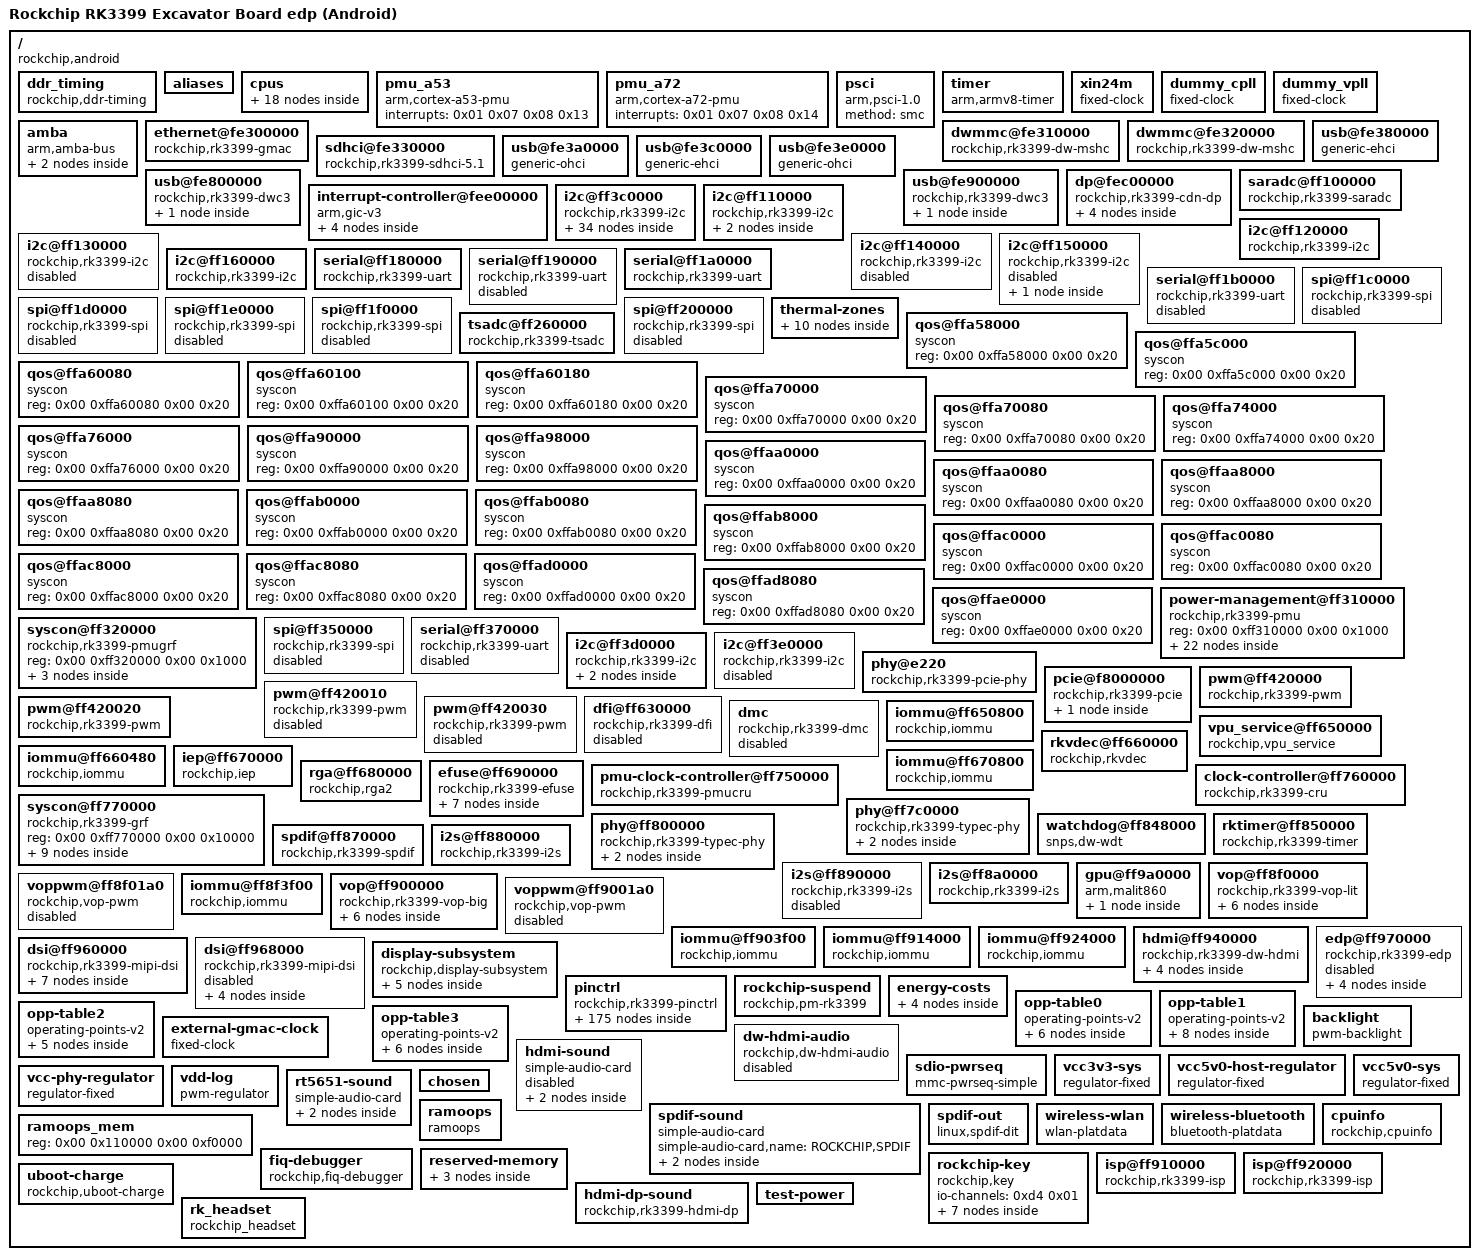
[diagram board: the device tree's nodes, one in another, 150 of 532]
/dts-v1/;

/ {
	compatible = "rockchip,android\0rockchip,rk3399-excavator-edp\0rockchip,rk3399";
	interrupt-parent = < 0x01 >;
	#address-cells = < 0x02 >;
	#size-cells = < 0x02 >;
	model = "Rockchip RK3399 Excavator Board edp (Android)";

	ddr_timing {
		compatible = "rockchip,ddr-timing";
		ddr3_speed_bin = < 0x15 >;
		pd_idle = < 0x00 >;
		sr_idle = < 0x00 >;
		sr_mc_gate_idle = < 0x00 >;
		srpd_lite_idle = < 0x00 >;
		standby_idle = < 0x00 >;
		auto_lp_dis_freq = < 0x29a >;
		ddr3_dll_dis_freq = < 0x12c >;
		phy_dll_dis_freq = < 0x104 >;
		ddr3_odt_dis_freq = < 0x29a >;
		ddr3_drv = < 0x28 >;
		ddr3_odt = < 0x78 >;
		phy_ddr3_ca_drv = < 0x28 >;
		phy_ddr3_dq_drv = < 0x28 >;
		phy_ddr3_odt = < 0xf0 >;
		lpddr3_odt_dis_freq = < 0x29a >;
		lpddr3_drv = < 0x22 >;
		lpddr3_odt = < 0xf0 >;
		phy_lpddr3_ca_drv = < 0x22 >;
		phy_lpddr3_dq_drv = < 0x22 >;
		phy_lpddr3_odt = < 0xf0 >;
		lpddr4_odt_dis_freq = < 0x3a5 >;
		lpddr4_drv = < 0x3c >;
		lpddr4_dq_odt = < 0x28 >;
		lpddr4_ca_odt = < 0x28 >;
		phy_lpddr4_ca_drv = < 0x28 >;
		phy_lpddr4_ck_cs_drv = < 0x50 >;
		phy_lpddr4_dq_drv = < 0x50 >;
		phy_lpddr4_odt = < 0x3c >;
		linux,phandle = < 0x8f >;
		phandle = < 0x8f >;
	};

	aliases {
		i2c0 = "/i2c@ff3c0000";
		i2c1 = "/i2c@ff110000";
		i2c2 = "/i2c@ff120000";
		i2c3 = "/i2c@ff130000";
		i2c4 = "/i2c@ff3d0000";
		i2c5 = "/i2c@ff140000";
		i2c6 = "/i2c@ff150000";
		i2c7 = "/i2c@ff160000";
		i2c8 = "/i2c@ff3e0000";
		serial0 = "/serial@ff180000";
		serial1 = "/serial@ff190000";
		serial2 = "/serial@ff1a0000";
		serial3 = "/serial@ff1b0000";
		serial4 = "/serial@ff370000";
		dsi0 = "/dsi@ff960000";
		dsi1 = "/dsi@ff968000";
	};

	cpus {
		#address-cells = < 0x02 >;
		#size-cells = < 0x00 >;

		cpu-map {

			cluster0 {

				core0 {
					cpu = < 0x02 >;
				};

				core1 {
					cpu = < 0x03 >;
				};

				core2 {
					cpu = < 0x04 >;
				};

				core3 {
					cpu = < 0x05 >;
				};
			};

			cluster1 {

				core0 {
					cpu = < 0x06 >;
				};

				core1 {
					cpu = < 0x07 >;
				};
			};
		};

		cpu@0 {
			device_type = "cpu";
			compatible = "arm,cortex-a53\0arm,armv8";
			reg = < 0x00 0x00 >;
			enable-method = "psci";
			#cooling-cells = < 0x02 >;
			dynamic-power-coefficient = < 0x64 >;
			clocks = < 0x08 0x08 >;
			cpu-idle-states = < 0x09 0x0a >;
			operating-points-v2 = < 0x0b >;
			sched-energy-costs = < 0x0c 0x0d >;
			cpu-supply = < 0x0e >;
			linux,phandle = < 0x02 >;
			phandle = < 0x02 >;
		};

		cpu@1 {
			device_type = "cpu";
			compatible = "arm,cortex-a53\0arm,armv8";
			reg = < 0x00 0x01 >;
			enable-method = "psci";
			clocks = < 0x08 0x08 >;
			cpu-idle-states = < 0x09 0x0a >;
			operating-points-v2 = < 0x0b >;
			sched-energy-costs = < 0x0c 0x0d >;
			cpu-supply = < 0x0e >;
			linux,phandle = < 0x03 >;
			phandle = < 0x03 >;
		};

		cpu@2 {
			device_type = "cpu";
			compatible = "arm,cortex-a53\0arm,armv8";
			reg = < 0x00 0x02 >;
			enable-method = "psci";
			clocks = < 0x08 0x08 >;
			cpu-idle-states = < 0x09 0x0a >;
			operating-points-v2 = < 0x0b >;
			sched-energy-costs = < 0x0c 0x0d >;
			cpu-supply = < 0x0e >;
			linux,phandle = < 0x04 >;
			phandle = < 0x04 >;
		};

		cpu@3 {
			device_type = "cpu";
			compatible = "arm,cortex-a53\0arm,armv8";
			reg = < 0x00 0x03 >;
			enable-method = "psci";
			clocks = < 0x08 0x08 >;
			cpu-idle-states = < 0x09 0x0a >;
			operating-points-v2 = < 0x0b >;
			sched-energy-costs = < 0x0c 0x0d >;
			cpu-supply = < 0x0e >;
			linux,phandle = < 0x05 >;
			phandle = < 0x05 >;
		};

		cpu@100 {
			device_type = "cpu";
			compatible = "arm,cortex-a72\0arm,armv8";
			reg = < 0x00 0x100 >;
			enable-method = "psci";
			#cooling-cells = < 0x02 >;
			dynamic-power-coefficient = < 0x1b4 >;
			clocks = < 0x08 0x09 >;
			cpu-idle-states = < 0x09 0x0a >;
			operating-points-v2 = < 0x0f >;
			sched-energy-costs = < 0x10 0x11 >;
			cpu-supply = < 0x12 >;
			linux,phandle = < 0x06 >;
			phandle = < 0x06 >;
		};

		cpu@101 {
			device_type = "cpu";
			compatible = "arm,cortex-a72\0arm,armv8";
			reg = < 0x00 0x101 >;
			enable-method = "psci";
			clocks = < 0x08 0x09 >;
			cpu-idle-states = < 0x09 0x0a >;
			operating-points-v2 = < 0x0f >;
			sched-energy-costs = < 0x10 0x11 >;
			cpu-supply = < 0x12 >;
			linux,phandle = < 0x07 >;
			phandle = < 0x07 >;
		};

		idle-states {
			entry-method = "psci";

			cpu-sleep {
				compatible = "arm,idle-state";
				local-timer-stop;
				arm,psci-suspend-param = < 0x10000 >;
				entry-latency-us = < 0x78 >;
				exit-latency-us = < 0xfa >;
				min-residency-us = < 0x384 >;
				linux,phandle = < 0x09 >;
				phandle = < 0x09 >;
			};

			cluster-sleep {
				compatible = "arm,idle-state";
				local-timer-stop;
				arm,psci-suspend-param = < 0x1010000 >;
				entry-latency-us = < 0x190 >;
				exit-latency-us = < 0x1f4 >;
				min-residency-us = < 0x7d0 >;
				linux,phandle = < 0x0a >;
				phandle = < 0x0a >;
			};
		};
	};

	pmu_a53 {
		compatible = "arm,cortex-a53-pmu";
		interrupts = < 0x01 0x07 0x08 0x13 >;
	};

	pmu_a72 {
		compatible = "arm,cortex-a72-pmu";
		interrupts = < 0x01 0x07 0x08 0x14 >;
	};

	psci {
		compatible = "arm,psci-1.0";
		method = "smc";
	};

	timer {
		compatible = "arm,armv8-timer";
		interrupts = < 0x01 0x0d 0x08 0x00 0x01 0x0e 0x08 0x00 0x01 0x0b 0x08 0x00 0x01 0x0a 0x08 0x00 >;
	};

	xin24m {
		compatible = "fixed-clock";
		clock-frequency = < 0x16e3600 >;
		clock-output-names = "xin24m";
		#clock-cells = < 0x00 >;
	};

	dummy_cpll {
		compatible = "fixed-clock";
		clock-frequency = < 0x00 >;
		clock-output-names = "dummy_cpll";
		#clock-cells = < 0x00 >;
	};

	dummy_vpll {
		compatible = "fixed-clock";
		clock-frequency = < 0x00 >;
		clock-output-names = "dummy_vpll";
		#clock-cells = < 0x00 >;
	};

	amba {
		compatible = "arm,amba-bus";
		#address-cells = < 0x02 >;
		#size-cells = < 0x02 >;
		ranges;

		dma-controller@ff6d0000 {
			compatible = "arm,pl330\0arm,primecell";
			reg = < 0x00 0xff6d0000 0x00 0x4000 >;
			interrupts = < 0x00 0x05 0x04 0x00 0x00 0x06 0x04 0x00 >;
			#dma-cells = < 0x01 >;
			clocks = < 0x08 0xd3 >;
			clock-names = "apb_pclk";
			peripherals-req-type-burst;
			linux,phandle = < 0x98 >;
			phandle = < 0x98 >;
		};

		dma-controller@ff6e0000 {
			compatible = "arm,pl330\0arm,primecell";
			reg = < 0x00 0xff6e0000 0x00 0x4000 >;
			interrupts = < 0x00 0x07 0x04 0x00 0x00 0x08 0x04 0x00 >;
			#dma-cells = < 0x01 >;
			clocks = < 0x08 0xd4 >;
			clock-names = "apb_pclk";
			peripherals-req-type-burst;
		};
	};

	ethernet@fe300000 {
		compatible = "rockchip,rk3399-gmac";
		reg = < 0x00 0xfe300000 0x00 0x10000 >;
		rockchip,grf = < 0x15 >;
		interrupts = < 0x00 0x0c 0x04 0x00 >;
		interrupt-names = "macirq";
		clocks = < 0x08 0x69 0x08 0x67 0x08 0x68 0x08 0x66 0x08 0x6a 0x08 0xd5 0x08 0x166 >;
		clock-names = "stmmaceth\0mac_clk_rx\0mac_clk_tx\0clk_mac_ref\0clk_mac_refout\0aclk_mac\0pclk_mac";
		resets = < 0x08 0x89 >;
		reset-names = "stmmaceth";
		power-domains = < 0x16 0x16 >;
		status = "okay";
		phy-supply = < 0x17 >;
		phy-mode = "rgmii";
		clock_in_out = "input";
		snps,reset-gpio = < 0x18 0x0f 0x01 >;
		snps,reset-active-low;
		snps,reset-delays-us = < 0x00 0x2710 0xc350 >;
		assigned-clocks = < 0x08 0xa6 >;
		assigned-clock-parents = < 0x19 >;
		pinctrl-names = "default";
		pinctrl-0 = < 0x1a >;
		tx_delay = < 0x28 >;
		rx_delay = < 0x11 >;
	};

	dwmmc@fe310000 {
		compatible = "rockchip,rk3399-dw-mshc\0rockchip,rk3288-dw-mshc";
		reg = < 0x00 0xfe310000 0x00 0x4000 >;
		interrupts = < 0x00 0x40 0x04 0x00 >;
		clock-freq-min-max = < 0x30d40 0x2faf080 >;
		clocks = < 0x08 0x1ee 0x08 0x4d 0x08 0x9c 0x08 0x9d >;
		clock-names = "biu\0ciu\0ciu-drive\0ciu-sample";
		fifo-depth = < 0x100 >;
		power-domains = < 0x16 0x1c >;
		status = "okay";
		clock-frequency = < 0x2faf080 >;
		supports-sdio;
		bus-width = < 0x04 >;
		disable-wp;
		cap-sd-highspeed;
		cap-sdio-irq;
		keep-power-in-suspend;
		mmc-pwrseq = < 0x1b >;
		non-removable;
		num-slots = < 0x01 >;
		pinctrl-names = "default";
		pinctrl-0 = < 0x1c 0x1d 0x1e >;
		sd-uhs-sdr104;
	};

	dwmmc@fe320000 {
		compatible = "rockchip,rk3399-dw-mshc\0rockchip,rk3288-dw-mshc";
		reg = < 0x00 0xfe320000 0x00 0x4000 >;
		interrupts = < 0x00 0x41 0x04 0x00 >;
		clock-freq-min-max = < 0x186a0 0x8f0d180 >;
		clocks = < 0x08 0x1ce 0x08 0x4c 0x08 0x9a 0x08 0x9b >;
		clock-names = "biu\0ciu\0ciu-drive\0ciu-sample";
		fifo-depth = < 0x100 >;
		power-domains = < 0x16 0x1b >;
		status = "okay";
		clock-frequency = < 0x8f0d180 >;
		supports-sd;
		bus-width = < 0x04 >;
		cap-mmc-highspeed;
		cap-sd-highspeed;
		disable-wp;
		num-slots = < 0x01 >;
		vqmmc-supply = < 0x1f >;
		pinctrl-names = "default";
		pinctrl-0 = < 0x20 0x21 0x22 0x23 >;
	};

	sdhci@fe330000 {
		compatible = "rockchip,rk3399-sdhci-5.1\0arasan,sdhci-5.1";
		reg = < 0x00 0xfe330000 0x00 0x10000 >;
		interrupts = < 0x00 0x0b 0x04 0x00 >;
		arasan,soc-ctl-syscon = < 0x15 >;
		assigned-clocks = < 0x08 0x4e >;
		assigned-clock-rates = < 0xbebc200 >;
		clocks = < 0x08 0x4e 0x08 0xf0 >;
		clock-names = "clk_xin\0clk_ahb";
		clock-output-names = "emmc_cardclock";
		#clock-cells = < 0x00 >;
		phys = < 0x24 >;
		phy-names = "phy_arasan";
		power-domains = < 0x16 0x17 >;
		status = "okay";
		bus-width = < 0x08 >;
		mmc-hs400-1_8v;
		supports-emmc;
		non-removable;
		keep-power-in-suspend;
		mmc-hs400-enhanced-strobe;
		assigned-clock-parents = < 0x08 0x05 >;
		linux,phandle = < 0x96 >;
		phandle = < 0x96 >;
	};

	usb@fe380000 {
		compatible = "generic-ehci";
		reg = < 0x00 0xfe380000 0x00 0x20000 >;
		interrupts = < 0x00 0x1a 0x04 0x00 >;
		clocks = < 0x08 0x1c8 0x08 0x1c9 0x08 0xa8 >;
		clock-names = "hclk_host0\0hclk_host0_arb\0usbphy0_480m";
		phys = < 0x25 >;
		phy-names = "usb";
		power-domains = < 0x16 0x0e >;
		status = "okay";
	};

	usb@fe3a0000 {
		compatible = "generic-ohci";
		reg = < 0x00 0xfe3a0000 0x00 0x20000 >;
		interrupts = < 0x00 0x1c 0x04 0x00 >;
		clocks = < 0x08 0x1c8 0x08 0x1c9 0x08 0xa8 >;
		clock-names = "hclk_host0\0hclk_host0_arb\0usbphy0_480m";
		phys = < 0x25 >;
		phy-names = "usb";
		power-domains = < 0x16 0x0e >;
		status = "okay";
	};

	usb@fe3c0000 {
		compatible = "generic-ehci";
		reg = < 0x00 0xfe3c0000 0x00 0x20000 >;
		interrupts = < 0x00 0x1e 0x04 0x00 >;
		clocks = < 0x08 0x1ca 0x08 0x1cb 0x08 0xa9 >;
		clock-names = "hclk_host1\0hclk_host1_arb\0usbphy1_480m";
		phys = < 0x26 >;
		phy-names = "usb";
		power-domains = < 0x16 0x0e >;
		status = "okay";
	};

	usb@fe3e0000 {
		compatible = "generic-ohci";
		reg = < 0x00 0xfe3e0000 0x00 0x20000 >;
		interrupts = < 0x00 0x20 0x04 0x00 >;
		clocks = < 0x08 0x1ca 0x08 0x1cb 0x08 0xa9 >;
		clock-names = "hclk_host1\0hclk_host1_arb\0usbphy1_480m";
		phys = < 0x26 >;
		phy-names = "usb";
		power-domains = < 0x16 0x0e >;
		status = "okay";
	};

	usb@fe800000 {
		compatible = "rockchip,rk3399-dwc3";
		clocks = < 0x08 0x81 0x08 0x83 0x08 0xf6 0x08 0xf9 >;
		clock-names = "ref_clk\0suspend_clk\0bus_clk\0grf_clk";
		power-domains = < 0x16 0x18 >;
		resets = < 0x08 0x125 >;
		reset-names = "usb3-otg";
		#address-cells = < 0x02 >;
		#size-cells = < 0x02 >;
		ranges;
		status = "okay";
		extcon = < 0x27 >;

		dwc3@fe800000 {
			compatible = "snps,dwc3";
			reg = < 0x00 0xfe800000 0x00 0x100000 >;
			interrupts = < 0x00 0x69 0x04 0x00 >;
			dr_mode = "otg";
			phys = < 0x28 0x29 >;
			phy-names = "usb2-phy\0usb3-phy";
			phy_type = "utmi_wide";
			snps,dis_enblslpm_quirk;
			snps,dis-u2-freeclk-exists-quirk;
			snps,dis_u2_susphy_quirk;
			snps,dis-del-phy-power-chg-quirk;
			snps,tx-ipgap-linecheck-dis-quirk;
			snps,xhci-slow-suspend-quirk;
			snps,usb3-warm-reset-on-resume-quirk;
			status = "okay";
		};
	};

	usb@fe900000 {
		compatible = "rockchip,rk3399-dwc3";
		clocks = < 0x08 0x82 0x08 0x84 0x08 0xf7 0x08 0xf9 >;
		clock-names = "ref_clk\0suspend_clk\0bus_clk\0grf_clk";
		power-domains = < 0x16 0x18 >;
		resets = < 0x08 0x126 >;
		reset-names = "usb3-otg";
		#address-cells = < 0x02 >;
		#size-cells = < 0x02 >;
		ranges;
		status = "okay";

		dwc3@fe900000 {
			compatible = "snps,dwc3";
			reg = < 0x00 0xfe900000 0x00 0x100000 >;
			interrupts = < 0x00 0x6e 0x04 0x00 >;
			dr_mode = "host";
			phys = < 0x2a 0x2b >;
			phy-names = "usb2-phy\0usb3-phy";
			phy_type = "utmi_wide";
			snps,dis_enblslpm_quirk;
			snps,dis-u2-freeclk-exists-quirk;
			snps,dis_u2_susphy_quirk;
			snps,dis-del-phy-power-chg-quirk;
			snps,tx-ipgap-linecheck-dis-quirk;
			snps,xhci-slow-suspend-quirk;
			snps,usb3-warm-reset-on-resume-quirk;
			status = "okay";
		};
	};

	dp@fec00000 {
		compatible = "rockchip,rk3399-cdn-dp";
		reg = < 0x00 0xfec00000 0x00 0x100000 >;
		interrupts = < 0x00 0x09 0x04 >;
		clocks = < 0x08 0x72 0x08 0x175 0x08 0xa1 0x08 0x16f >;
		clock-names = "core-clk\0pclk\0spdif\0grf";
		assigned-clocks = < 0x08 0x72 >;
		assigned-clock-rates = < 0x5f5e100 >;
		power-domains = < 0x16 0x15 >;
		phys = < 0x2c >;
		resets = < 0x08 0x103 0x08 0x148 0x08 0x14a 0x08 0xfd >;
		reset-names = "spdif\0dptx\0apb\0core";
		rockchip,grf = < 0x15 >;
		#address-cells = < 0x01 >;
		#size-cells = < 0x00 >;
		#sound-dai-cells = < 0x01 >;
		status = "okay";
		extcon = < 0x27 >;
		linux,phandle = < 0xdc >;
		phandle = < 0xdc >;

		ports {
			#address-cells = < 0x01 >;
			#size-cells = < 0x00 >;

			port {
				#address-cells = < 0x01 >;
				#size-cells = < 0x00 >;

				endpoint@0 {
					reg = < 0x00 >;
					remote-endpoint = < 0x2d >;
					status = "disabled";
					linux,phandle = < 0xa9 >;
					phandle = < 0xa9 >;
				};

				endpoint@1 {
					reg = < 0x01 >;
					remote-endpoint = < 0x2e >;
					linux,phandle = < 0xa2 >;
					phandle = < 0xa2 >;
				};
			};
		};
	};

	interrupt-controller@fee00000 {
		compatible = "arm,gic-v3";
		#interrupt-cells = < 0x04 >;
		#address-cells = < 0x02 >;
		#size-cells = < 0x02 >;
		ranges;
		interrupt-controller;
		reg = < 0x00 0xfee00000 0x00 0x10000 0x00 0xfef00000 0x00 0xc0000 0x00 0xfff00000 0x00 0x10000 0x00 0xfff10000 0x00 0x10000 0x00 0xfff20000 0x00 0x10000 >;
		interrupts = < 0x01 0x09 0x04 0x00 >;
		linux,phandle = < 0x01 >;
		phandle = < 0x01 >;

		interrupt-controller@fee20000 {
			compatible = "arm,gic-v3-its";
			msi-controller;
			reg = < 0x00 0xfee20000 0x00 0x20000 >;
			linux,phandle = < 0x84 >;
			phandle = < 0x84 >;
		};

		ppi-partitions {

			interrupt-partition-0 {
				affinity = < 0x02 0x03 0x04 0x05 >;
				linux,phandle = < 0x13 >;
				phandle = < 0x13 >;
			};

			interrupt-partition-1 {
				affinity = < 0x06 0x07 >;
				linux,phandle = < 0x14 >;
				phandle = < 0x14 >;
			};
		};
	};

	saradc@ff100000 {
		compatible = "rockchip,rk3399-saradc";
		reg = < 0x00 0xff100000 0x00 0x100 >;
		interrupts = < 0x00 0x3e 0x04 0x00 >;
		#io-channel-cells = < 0x01 >;
		clocks = < 0x08 0x50 0x08 0x165 >;
		clock-names = "saradc\0apb_pclk";
		resets = < 0x08 0xd4 >;
		reset-names = "saradc-apb";
		status = "okay";
		linux,phandle = < 0xd4 >;
		phandle = < 0xd4 >;
	};

	i2c@ff3c0000 {
		compatible = "rockchip,rk3399-i2c";
		reg = < 0x00 0xff3c0000 0x00 0x1000 >;
		clocks = < 0x2f 0x09 0x2f 0x1b >;
		clock-names = "i2c\0pclk";
		interrupts = < 0x00 0x39 0x04 0x00 >;
		pinctrl-names = "default";
		pinctrl-0 = < 0x30 >;
		#address-cells = < 0x01 >;
		#size-cells = < 0x00 >;
		status = "okay";
		i2c-scl-rising-time-ns = < 0xa8 >;
		i2c-scl-falling-time-ns = < 0x04 >;
		clock-frequency = < 0x61a80 >;

		syr827@40 {
			compatible = "silergy,syr827";
			reg = < 0x40 >;
			vin-supply = < 0x31 >;
			regulator-compatible = "fan53555-reg";
			pinctrl-names = "default";
			pinctrl-0 = < 0x32 >;
			vsel-gpios = < 0x33 0x11 0x00 >;
			regulator-name = "vdd_cpu_b";
			regulator-min-microvolt = < 0xadf34 >;
			regulator-max-microvolt = < 0x16e360 >;
			regulator-ramp-delay = < 0x3e8 >;
			fcs,suspend-voltage-selector = < 0x01 >;
			regulator-always-on;
			regulator-boot-on;
			regulator-initial-state = < 0x03 >;
			linux,phandle = < 0x12 >;
			phandle = < 0x12 >;

			regulator-state-mem {
				regulator-off-in-suspend;
			};
		};

		syr828@41 {
			compatible = "silergy,syr828";
			reg = < 0x41 >;
			vin-supply = < 0x31 >;
			regulator-compatible = "fan53555-reg";
			pinctrl-names = "default";
			pinctrl-0 = < 0x34 >;
			vsel-gpios = < 0x33 0x0e 0x00 >;
			regulator-name = "vdd_gpu";
			regulator-min-microvolt = < 0xadf34 >;
			regulator-max-microvolt = < 0x16e360 >;
			regulator-ramp-delay = < 0x3e8 >;
			fcs,suspend-voltage-selector = < 0x01 >;
			regulator-always-on;
			regulator-boot-on;
			regulator-initial-state = < 0x03 >;
			linux,phandle = < 0x9d >;
			phandle = < 0x9d >;

			regulator-state-mem {
				regulator-off-in-suspend;
			};
		};

		pmic@1b {
			compatible = "rockchip,rk808";
			reg = < 0x1b >;
			interrupt-parent = < 0x33 >;
			interrupts = < 0x15 0x08 >;
			pinctrl-names = "default";
			pinctrl-0 = < 0x35 0x36 >;
			rockchip,system-power-controller;
			wakeup-source;
			#clock-cells = < 0x01 >;
			clock-output-names = "xin32k\0rk808-clkout2";
			vcc1-supply = < 0x37 >;
			vcc2-supply = < 0x37 >;
			vcc3-supply = < 0x37 >;
			vcc4-supply = < 0x37 >;
			vcc6-supply = < 0x37 >;
			vcc7-supply = < 0x37 >;
			vcc8-supply = < 0x37 >;
			vcc9-supply = < 0x37 >;
			vcc10-supply = < 0x37 >;
			vcc11-supply = < 0x37 >;
			vcc12-supply = < 0x37 >;
			vddio-supply = < 0x38 >;
			linux,phandle = < 0xc8 >;
			phandle = < 0xc8 >;

			regulators {

				DCDC_REG1 {
					regulator-always-on;
					regulator-boot-on;
					regulator-min-microvolt = < 0xb71b0 >;
					regulator-max-microvolt = < 0x149970 >;
					regulator-ramp-delay = < 0x1771 >;
					regulator-name = "vdd_center";

					regulator-state-mem {
						regulator-off-in-suspend;
					};
				};

				DCDC_REG2 {
					regulator-always-on;
					regulator-boot-on;
					regulator-min-microvolt = < 0xb71b0 >;
					regulator-max-microvolt = < 0x149970 >;
					regulator-ramp-delay = < 0x1771 >;
					regulator-name = "vdd_cpu_l";
					linux,phandle = < 0x0e >;
					phandle = < 0x0e >;

					regulator-state-mem {
						regulator-off-in-suspend;
					};
				};

				DCDC_REG3 {
					regulator-always-on;
					regulator-boot-on;
					regulator-name = "vcc_ddr";

					regulator-state-mem {
						regulator-on-in-suspend;
					};
				};

				DCDC_REG4 {
					regulator-always-on;
					regulator-boot-on;
					regulator-min-microvolt = < 0x1b7740 >;
					regulator-max-microvolt = < 0x1b7740 >;
					regulator-name = "vcc_1v8";

					regulator-state-mem {
						regulator-on-in-suspend;
						regulator-suspend-microvolt = < 0x1b7740 >;
					};
				};

				LDO_REG1 {
					regulator-always-on;
					regulator-boot-on;
					regulator-min-microvolt = < 0x1b7740 >;
					regulator-max-microvolt = < 0x1b7740 >;
					regulator-name = "vcc1v8_dvp";
					linux,phandle = < 0x94 >;
					phandle = < 0x94 >;

					regulator-state-mem {
						regulator-off-in-suspend;
					};
				};

				LDO_REG2 {
					regulator-always-on;
					regulator-boot-on;
					regulator-min-microvolt = < 0x2dc6c0 >;
					regulator-max-microvolt = < 0x2dc6c0 >;
					regulator-name = "vcc3v0_tp";

					regulator-state-mem {
						regulator-off-in-suspend;
					};
				};

				LDO_REG3 {
					regulator-always-on;
					regulator-boot-on;
					regulator-min-microvolt = < 0x1b7740 >;
					regulator-max-microvolt = < 0x1b7740 >;
					regulator-name = "vcc1v8_pmu";
					linux,phandle = < 0x38 >;
					phandle = < 0x38 >;

					regulator-state-mem {
						regulator-on-in-suspend;
						regulator-suspend-microvolt = < 0x1b7740 >;
					};
				};

				LDO_REG4 {
					regulator-always-on;
					regulator-boot-on;
					regulator-min-microvolt = < 0x1b7740 >;
					regulator-max-microvolt = < 0x325aa0 >;
					regulator-name = "vcc_sd";
					linux,phandle = < 0x1f >;
					phandle = < 0x1f >;

					regulator-state-mem {
						regulator-on-in-suspend;
						regulator-suspend-microvolt = < 0x325aa0 >;
					};
				};

				LDO_REG5 {
					regulator-always-on;
					regulator-boot-on;
					regulator-min-microvolt = < 0x2dc6c0 >;
					regulator-max-microvolt = < 0x2dc6c0 >;
					regulator-name = "vcca3v0_codec";

					regulator-state-mem {
						regulator-off-in-suspend;
					};
				};

				LDO_REG6 {
					regulator-always-on;
					regulator-boot-on;
					regulator-min-microvolt = < 0x16e360 >;
					regulator-max-microvolt = < 0x16e360 >;
					regulator-name = "vcc_1v5";

					regulator-state-mem {
						regulator-on-in-suspend;
						regulator-suspend-microvolt = < 0x16e360 >;
					};
				};

				LDO_REG7 {
					regulator-always-on;
					regulator-boot-on;
					regulator-min-microvolt = < 0x1b7740 >;
					regulator-max-microvolt = < 0x1b7740 >;
					regulator-name = "vcca1v8_codec";
					linux,phandle = < 0x95 >;
					phandle = < 0x95 >;

					regulator-state-mem {
						regulator-off-in-suspend;
					};
				};

				LDO_REG8 {
					regulator-always-on;
					regulator-boot-on;
					regulator-min-microvolt = < 0x2dc6c0 >;
					regulator-max-microvolt = < 0x2dc6c0 >;
					regulator-name = "vcc_3v0";
					linux,phandle = < 0x7b >;
					phandle = < 0x7b >;

					regulator-state-mem {
						regulator-on-in-suspend;
						regulator-suspend-microvolt = < 0x2dc6c0 >;
					};
				};

				SWITCH_REG1 {
					regulator-always-on;
					regulator-boot-on;
					regulator-name = "vcc3v3_s3";

					regulator-state-mem {
						regulator-off-in-suspend;
					};
				};

				SWITCH_REG2 {
					regulator-boot-on;
					regulator-name = "vcc3v3_s0";
					linux,phandle = < 0xb2 >;
					phandle = < 0xb2 >;

					regulator-state-mem {
						regulator-off-in-suspend;
					};
				};
			};
		};
	};

	i2c@ff110000 {
		compatible = "rockchip,rk3399-i2c";
		reg = < 0x00 0xff110000 0x00 0x1000 >;
		clocks = < 0x08 0x41 0x08 0x155 >;
		clock-names = "i2c\0pclk";
		interrupts = < 0x00 0x3b 0x04 0x00 >;
		pinctrl-names = "default";
		pinctrl-0 = < 0x39 >;
		#address-cells = < 0x01 >;
		#size-cells = < 0x00 >;
		status = "okay";
		i2c-scl-rising-time-ns = < 0x12c >;
		i2c-scl-falling-time-ns = < 0x0f >;

		rt5651@1a {
			#sound-dai-cells = < 0x00 >;
			compatible = "rockchip,rt5651";
			reg = < 0x1a >;
			clocks = < 0x08 0x59 >;
			clock-names = "mclk";
			pinctrl-names = "default";
			pinctrl-0 = < 0x3a >;
			spk-con-gpio = < 0x3b 0x0b 0x00 >;
			hp-det-gpio = < 0x3c 0x1c 0x01 >;
			status = "okay";
			linux,phandle = < 0xcd >;
			phandle = < 0xcd >;
		};

		gsl3673@40 {
			compatible = "GSL,GSL3673";
			reg = < 0x40 >;
			screen_max_x = < 0x600 >;
			screen_max_y = < 0x800 >;
			irq_gpio_number = < 0x33 0x14 0x08 >;
			rst_gpio_number = < 0x3c 0x16 0x00 >;
		};
	};

	i2c@ff120000 {
		compatible = "rockchip,rk3399-i2c";
		reg = < 0x00 0xff120000 0x00 0x1000 >;
		clocks = < 0x08 0x42 0x08 0x156 >;
		clock-names = "i2c\0pclk";
		interrupts = < 0x00 0x23 0x04 0x00 >;
		pinctrl-names = "default";
		pinctrl-0 = < 0x3d >;
		#address-cells = < 0x01 >;
		#size-cells = < 0x00 >;
		status = "okay";
	};

	i2c@ff130000 {
		compatible = "rockchip,rk3399-i2c";
		reg = < 0x00 0xff130000 0x00 0x1000 >;
		clocks = < 0x08 0x43 0x08 0x157 >;
		clock-names = "i2c\0pclk";
		interrupts = < 0x00 0x22 0x04 0x00 >;
		pinctrl-names = "default";
		pinctrl-0 = < 0x3e >;
		#address-cells = < 0x01 >;
		#size-cells = < 0x00 >;
		status = "disabled";
	};

	i2c@ff140000 {
		compatible = "rockchip,rk3399-i2c";
		reg = < 0x00 0xff140000 0x00 0x1000 >;
		clocks = < 0x08 0x44 0x08 0x158 >;
		clock-names = "i2c\0pclk";
		interrupts = < 0x00 0x26 0x04 0x00 >;
		pinctrl-names = "default";
		pinctrl-0 = < 0x3f >;
		#address-cells = < 0x01 >;
		#size-cells = < 0x00 >;
		status = "disabled";
	};

	i2c@ff150000 {
		compatible = "rockchip,rk3399-i2c";
		reg = < 0x00 0xff150000 0x00 0x1000 >;
		clocks = < 0x08 0x45 0x08 0x159 >;
		clock-names = "i2c\0pclk";
		interrupts = < 0x00 0x25 0x04 0x00 >;
		pinctrl-names = "default";
		pinctrl-0 = < 0x40 >;
		#address-cells = < 0x01 >;
		#size-cells = < 0x00 >;
		status = "disabled";

		cw2015@62 {
			status = "disabled";
			compatible = "cw201x";
			reg = < 0x62 >;
			bat_config_info = < 0x15 0x42 0x60 0x59 0x52 0x58 0x4d 0x48 0x48 0x44 0x44 0x46 0x49 0x48 0x32 0x24 0x20 0x17 0x13 0x0f 0x19 0x3e 0x51 0x45 0x08 0x76 0x0b 0x85 0x0e 0x1c 0x2e 0x3e 0x4d 0x52 0x52 0x57 0x3d 0x1b 0x6a 0x2d 0x25 0x43 0x52 0x87 0x8f 0x91 0x94 0x52 0x82 0x8c 0x92 0x96 0xff 0x7b 0xbb 0xcb 0x2f 0x7d 0x72 0xa5 0xb5 0xc1 0x46 0xae >;
			monitor_sec = < 0x05 >;
			virtual_power = < 0x00 >;
		};
	};

	i2c@ff160000 {
		compatible = "rockchip,rk3399-i2c";
		reg = < 0x00 0xff160000 0x00 0x1000 >;
		clocks = < 0x08 0x46 0x08 0x15a >;
		clock-names = "i2c\0pclk";
		interrupts = < 0x00 0x24 0x04 0x00 >;
		pinctrl-names = "default";
		pinctrl-0 = < 0x41 >;
		#address-cells = < 0x01 >;
		#size-cells = < 0x00 >;
		status = "okay";
	};

	serial@ff180000 {
		compatible = "rockchip,rk3399-uart\0snps,dw-apb-uart";
		reg = < 0x00 0xff180000 0x00 0x100 >;
		clocks = < 0x08 0x51 0x08 0x160 >;
		clock-names = "baudclk\0apb_pclk";
		interrupts = < 0x00 0x63 0x04 0x00 >;
		reg-shift = < 0x02 >;
		reg-io-width = < 0x04 >;
		pinctrl-names = "default";
		pinctrl-0 = < 0x42 0x43 >;
		status = "okay";
		assigned-clocks = < 0x08 0xac >;
		assigned-clock-parents = < 0x08 0x05 >;
	};

	serial@ff190000 {
		compatible = "rockchip,rk3399-uart\0snps,dw-apb-uart";
		reg = < 0x00 0xff190000 0x00 0x100 >;
		clocks = < 0x08 0x52 0x08 0x161 >;
		clock-names = "baudclk\0apb_pclk";
		interrupts = < 0x00 0x62 0x04 0x00 >;
		reg-shift = < 0x02 >;
		reg-io-width = < 0x04 >;
		pinctrl-names = "default";
		pinctrl-0 = < 0x44 >;
		status = "disabled";
		assigned-clocks = < 0x08 0xad >;
		assigned-clock-parents = < 0x08 0x05 >;
	};

	serial@ff1a0000 {
		compatible = "rockchip,rk3399-uart\0snps,dw-apb-uart";
		reg = < 0x00 0xff1a0000 0x00 0x100 >;
		clocks = < 0x08 0x53 0x08 0x162 >;
		clock-names = "baudclk\0apb_pclk";
		interrupts = < 0x00 0x64 0x04 0x00 >;
		reg-shift = < 0x02 >;
		reg-io-width = < 0x04 >;
		pinctrl-names = "default";
		pinctrl-0 = < 0x45 >;
		status = "okay";
		assigned-clocks = < 0x08 0xad >;
		assigned-clock-parents = < 0x08 0x05 >;
	};

	serial@ff1b0000 {
		compatible = "rockchip,rk3399-uart\0snps,dw-apb-uart";
		reg = < 0x00 0xff1b0000 0x00 0x100 >;
		clocks = < 0x08 0x54 0x08 0x163 >;
		clock-names = "baudclk\0apb_pclk";
		interrupts = < 0x00 0x65 0x04 0x00 >;
		reg-shift = < 0x02 >;
		reg-io-width = < 0x04 >;
		pinctrl-names = "default";
		pinctrl-0 = < 0x46 0x47 0x48 >;
		status = "disabled";
		assigned-clocks = < 0x08 0xad >;
		assigned-clock-parents = < 0x08 0x05 >;
	};

	spi@ff1c0000 {
		compatible = "rockchip,rk3399-spi\0rockchip,rk3066-spi";
		reg = < 0x00 0xff1c0000 0x00 0x1000 >;
		clocks = < 0x08 0x47 0x08 0x15b >;
		clock-names = "spiclk\0apb_pclk";
		interrupts = < 0x00 0x44 0x04 0x00 >;
		pinctrl-names = "default";
		pinctrl-0 = < 0x49 0x4a 0x4b 0x4c >;
		#address-cells = < 0x01 >;
		#size-cells = < 0x00 >;
		status = "disabled";
	};

	spi@ff1d0000 {
		compatible = "rockchip,rk3399-spi\0rockchip,rk3066-spi";
		reg = < 0x00 0xff1d0000 0x00 0x1000 >;
		clocks = < 0x08 0x48 0x08 0x15c >;
		clock-names = "spiclk\0apb_pclk";
		interrupts = < 0x00 0x35 0x04 0x00 >;
		pinctrl-names = "default";
		pinctrl-0 = < 0x4d 0x4e 0x4f 0x50 >;
		#address-cells = < 0x01 >;
		#size-cells = < 0x00 >;
		status = "disabled";
	};

	spi@ff1e0000 {
		compatible = "rockchip,rk3399-spi\0rockchip,rk3066-spi";
		reg = < 0x00 0xff1e0000 0x00 0x1000 >;
		clocks = < 0x08 0x49 0x08 0x15d >;
		clock-names = "spiclk\0apb_pclk";
		interrupts = < 0x00 0x34 0x04 0x00 >;
		pinctrl-names = "default";
		pinctrl-0 = < 0x51 0x52 0x53 0x54 >;
		#address-cells = < 0x01 >;
		#size-cells = < 0x00 >;
		status = "disabled";
	};

	spi@ff1f0000 {
		compatible = "rockchip,rk3399-spi\0rockchip,rk3066-spi";
		reg = < 0x00 0xff1f0000 0x00 0x1000 >;
		clocks = < 0x08 0x4a 0x08 0x15e >;
		clock-names = "spiclk\0apb_pclk";
		interrupts = < 0x00 0x43 0x04 0x00 >;
		pinctrl-names = "default";
		pinctrl-0 = < 0x55 0x56 0x57 0x58 >;
		#address-cells = < 0x01 >;
		#size-cells = < 0x00 >;
		status = "disabled";
	};

	spi@ff200000 {
		compatible = "rockchip,rk3399-spi\0rockchip,rk3066-spi";
		reg = < 0x00 0xff200000 0x00 0x1000 >;
		clocks = < 0x08 0x4b 0x08 0x15f >;
		clock-names = "spiclk\0apb_pclk";
		interrupts = < 0x00 0x84 0x04 0x00 >;
		pinctrl-names = "default";
		pinctrl-0 = < 0x59 0x5a 0x5b 0x5c >;
		#address-cells = < 0x01 >;
		#size-cells = < 0x00 >;
		status = "disabled";
	};

	thermal-zones {

		soc-thermal {
			polling-delay-passive = < 0x14 >;
			polling-delay = < 0x3e8 >;
			sustainable-power = < 0x3e8 >;
			thermal-sensors = < 0x5d 0x00 >;

			trips {

				trip-point@0 {
					temperature = < 0x11170 >;
					hysteresis = < 0x7d0 >;
					type = "passive";
				};

				trip-point@1 {
					temperature = < 0x14c08 >;
					hysteresis = < 0x7d0 >;
					type = "passive";
					linux,phandle = < 0x5e >;
					phandle = < 0x5e >;
				};

				soc-crit {
					temperature = < 0x17318 >;
					hysteresis = < 0x7d0 >;
					type = "critical";
				};
			};

			cooling-maps {

				map0 {
					trip = < 0x5e >;
					cooling-device = < 0x02 0xffffffff 0xffffffff >;
					contribution = < 0x1000 >;
				};

				map1 {
					trip = < 0x5e >;
					cooling-device = < 0x06 0xffffffff 0xffffffff >;
					contribution = < 0x400 >;
				};

				map2 {
					trip = < 0x5e >;
					cooling-device = < 0x5f 0xffffffff 0xffffffff >;
					contribution = < 0x1000 >;
				};
			};
		};

		gpu-thermal {
			polling-delay-passive = < 0x64 >;
			polling-delay = < 0x3e8 >;
			thermal-sensors = < 0x5d 0x01 >;
		};
	};

	tsadc@ff260000 {
		compatible = "rockchip,rk3399-tsadc";
		reg = < 0x00 0xff260000 0x00 0x100 >;
		interrupts = < 0x00 0x61 0x04 0x00 >;
		rockchip,grf = < 0x15 >;
		clocks = < 0x08 0x4f 0x08 0x164 >;
		clock-names = "tsadc\0apb_pclk";
		assigned-clocks = < 0x08 0x4f >;
		assigned-clock-rates = < 0xb71b0 >;
		resets = < 0x08 0xe8 >;
		reset-names = "tsadc-apb";
		pinctrl-names = "init\0default\0sleep";
		pinctrl-0 = < 0x60 >;
		pinctrl-1 = < 0x61 >;
		pinctrl-2 = < 0x60 >;
		#thermal-sensor-cells = < 0x01 >;
		rockchip,hw-tshut-temp = < 0x17318 >;
		status = "okay";
		rockchip,hw-tshut-mode = < 0x01 >;
		rockchip,hw-tshut-polarity = < 0x01 >;
		linux,phandle = < 0x5d >;
		phandle = < 0x5d >;
	};

	qos@ffa58000 {
		compatible = "syscon";
		reg = < 0x00 0xffa58000 0x00 0x20 >;
		linux,phandle = < 0x69 >;
		phandle = < 0x69 >;
	};

	qos@ffa5c000 {
		compatible = "syscon";
		reg = < 0x00 0xffa5c000 0x00 0x20 >;
		linux,phandle = < 0x6a >;
		phandle = < 0x6a >;
	};

	qos@ffa60080 {
		compatible = "syscon";
		reg = < 0x00 0xffa60080 0x00 0x20 >;
		linux,phandle = < 0x6c >;
		phandle = < 0x6c >;
	};

	qos@ffa60100 {
		compatible = "syscon";
		reg = < 0x00 0xffa60100 0x00 0x20 >;
		linux,phandle = < 0x6d >;
		phandle = < 0x6d >;
	};

	qos@ffa60180 {
		compatible = "syscon";
		reg = < 0x00 0xffa60180 0x00 0x20 >;
		linux,phandle = < 0x6e >;
		phandle = < 0x6e >;
	};

	qos@ffa70000 {
		compatible = "syscon";
		reg = < 0x00 0xffa70000 0x00 0x20 >;
		linux,phandle = < 0x71 >;
		phandle = < 0x71 >;
	};

	qos@ffa70080 {
		compatible = "syscon";
		reg = < 0x00 0xffa70080 0x00 0x20 >;
		linux,phandle = < 0x72 >;
		phandle = < 0x72 >;
	};

	qos@ffa74000 {
		compatible = "syscon";
		reg = < 0x00 0xffa74000 0x00 0x20 >;
		linux,phandle = < 0x6f >;
		phandle = < 0x6f >;
	};

	qos@ffa76000 {
		compatible = "syscon";
		reg = < 0x00 0xffa76000 0x00 0x20 >;
		linux,phandle = < 0x70 >;
		phandle = < 0x70 >;
	};

	qos@ffa90000 {
		compatible = "syscon";
		reg = < 0x00 0xffa90000 0x00 0x20 >;
		linux,phandle = < 0x73 >;
		phandle = < 0x73 >;
	};

	qos@ffa98000 {
		compatible = "syscon";
		reg = < 0x00 0xffa98000 0x00 0x20 >;
		linux,phandle = < 0x62 >;
		phandle = < 0x62 >;
	};

	qos@ffaa0000 {
		compatible = "syscon";
		reg = < 0x00 0xffaa0000 0x00 0x20 >;
		linux,phandle = < 0x74 >;
		phandle = < 0x74 >;
	};

	qos@ffaa0080 {
		compatible = "syscon";
		reg = < 0x00 0xffaa0080 0x00 0x20 >;
		linux,phandle = < 0x75 >;
		phandle = < 0x75 >;
	};

	qos@ffaa8000 {
		compatible = "syscon";
		reg = < 0x00 0xffaa8000 0x00 0x20 >;
		linux,phandle = < 0x76 >;
		phandle = < 0x76 >;
	};

	qos@ffaa8080 {
		compatible = "syscon";
		reg = < 0x00 0xffaa8080 0x00 0x20 >;
		linux,phandle = < 0x77 >;
		phandle = < 0x77 >;
	};

	qos@ffab0000 {
		compatible = "syscon";
		reg = < 0x00 0xffab0000 0x00 0x20 >;
		linux,phandle = < 0x63 >;
		phandle = < 0x63 >;
	};

	qos@ffab0080 {
		compatible = "syscon";
		reg = < 0x00 0xffab0080 0x00 0x20 >;
		linux,phandle = < 0x64 >;
		phandle = < 0x64 >;
	};

	qos@ffab8000 {
		compatible = "syscon";
		reg = < 0x00 0xffab8000 0x00 0x20 >;
		linux,phandle = < 0x65 >;
		phandle = < 0x65 >;
	};

	qos@ffac0000 {
		compatible = "syscon";
		reg = < 0x00 0xffac0000 0x00 0x20 >;
		linux,phandle = < 0x66 >;
		phandle = < 0x66 >;
	};

	qos@ffac0080 {
		compatible = "syscon";
		reg = < 0x00 0xffac0080 0x00 0x20 >;
		linux,phandle = < 0x67 >;
		phandle = < 0x67 >;
	};

	qos@ffac8000 {
		compatible = "syscon";
		reg = < 0x00 0xffac8000 0x00 0x20 >;
		linux,phandle = < 0x78 >;
		phandle = < 0x78 >;
	};

	qos@ffac8080 {
		compatible = "syscon";
		reg = < 0x00 0xffac8080 0x00 0x20 >;
		linux,phandle = < 0x79 >;
		phandle = < 0x79 >;
	};

	qos@ffad0000 {
		compatible = "syscon";
		reg = < 0x00 0xffad0000 0x00 0x20 >;
		linux,phandle = < 0x7a >;
		phandle = < 0x7a >;
	};

	qos@ffad8080 {
		compatible = "syscon";
		reg = < 0x00 0xffad8080 0x00 0x20 >;
		linux,phandle = < 0x6b >;
		phandle = < 0x6b >;
	};

	qos@ffae0000 {
		compatible = "syscon";
		reg = < 0x00 0xffae0000 0x00 0x20 >;
		linux,phandle = < 0x68 >;
		phandle = < 0x68 >;
	};

	power-management@ff310000 {
		compatible = "rockchip,rk3399-pmu\0syscon\0simple-mfd";
		reg = < 0x00 0xff310000 0x00 0x1000 >;

		power-controller {
			compatible = "rockchip,rk3399-power-controller";
			#power-domain-cells = < 0x01 >;
			#address-cells = < 0x01 >;
			#size-cells = < 0x00 >;
			linux,phandle = < 0x16 >;
			phandle = < 0x16 >;

			pd_iep@34 {
				reg = < 0x22 >;
				clocks = < 0x08 0xe1 0x08 0x1dd >;
				pm_qos = < 0x62 >;
			};

			pd_rga@33 {
				reg = < 0x21 >;
				clocks = < 0x08 0xdc 0x08 0x1e5 >;
				pm_qos = < 0x63 0x64 >;
			};

			pd_vcodec@31 {
				reg = < 0x1f >;
				clocks = < 0x08 0xeb 0x08 0x1ea >;
				pm_qos = < 0x65 >;
			};

			pd_vdu@32 {
				reg = < 0x20 >;
				clocks = < 0x08 0xed 0x08 0x1ec >;
				pm_qos = < 0x66 0x67 >;
			};

			pd_gpu@35 {
				reg = < 0x23 >;
				clocks = < 0x08 0xd0 >;
				pm_qos = < 0x68 >;
			};

			pd_edp@25 {
				reg = < 0x19 >;
				clocks = < 0x08 0x16c >;
			};

			pd_emmc@23 {
				reg = < 0x17 >;
				clocks = < 0x08 0xf0 >;
				pm_qos = < 0x69 >;
			};

			pd_gmac@22 {
				reg = < 0x16 >;
				clocks = < 0x08 0xd5 0x08 0x166 >;
				pm_qos = < 0x6a >;
			};

			pd_perihp@14 {
				reg = < 0x0e >;
				#address-cells = < 0x01 >;
				#size-cells = < 0x00 >;
				clocks = < 0x08 0xc0 >;
				pm_qos = < 0x6b 0x6c 0x6d 0x6e >;

				pd_sd@27 {
					reg = < 0x1b >;
					clocks = < 0x08 0x1ce 0x08 0x4c >;
					pm_qos = < 0x6f >;
				};
			};

			pd_sdioaudio@28 {
				reg = < 0x1c >;
				clocks = < 0x08 0x1ee >;
				pm_qos = < 0x70 >;
			};

			pd_usb3@24 {
				reg = < 0x18 >;
				clocks = < 0x08 0xf4 >;
				pm_qos = < 0x71 0x72 >;
			};

			pd_vio@15 {
				reg = < 0x0f >;
				#address-cells = < 0x01 >;
				#size-cells = < 0x00 >;

				pd_hdcp@21 {
					reg = < 0x15 >;
					clocks = < 0x08 0xde 0x08 0x1e7 0x08 0x172 >;
					pm_qos = < 0x73 >;
				};

				pd_isp0@19 {
					reg = < 0x13 >;
					clocks = < 0x08 0xe5 0x08 0x1df >;
					pm_qos = < 0x74 0x75 >;
				};

				pd_isp1@20 {
					reg = < 0x14 >;
					clocks = < 0x08 0xe6 0x08 0x1e0 >;
					pm_qos = < 0x76 0x77 >;
				};

				pd_tcpc0@RK3399_PD_TCPC0 {
					reg = < 0x08 >;
					clocks = < 0x08 0x7e 0x08 0x7d >;
				};

				pd_tcpc1@RK3399_PD_TCPC1 {
					reg = < 0x09 >;
					clocks = < 0x08 0x80 0x08 0x7f >;
				};

				pd_vo@16 {
					reg = < 0x10 >;
					#address-cells = < 0x01 >;
					#size-cells = < 0x00 >;

					pd_vopb@17 {
						reg = < 0x11 >;
						clocks = < 0x08 0xd9 0x08 0x1d9 >;
						pm_qos = < 0x78 0x79 >;
					};

					pd_vopl@18 {
						reg = < 0x12 >;
						clocks = < 0x08 0xdb 0x08 0x1db >;
						pm_qos = < 0x7a >;
					};
				};
			};
		};
	};

	syscon@ff320000 {
		compatible = "rockchip,rk3399-pmugrf\0syscon\0simple-mfd";
		reg = < 0x00 0xff320000 0x00 0x1000 >;
		#address-cells = < 0x01 >;
		#size-cells = < 0x01 >;
		linux,phandle = < 0x8d >;
		phandle = < 0x8d >;

		io-domains {
			compatible = "rockchip,rk3399-pmu-io-voltage-domain";
			status = "okay";
			pmu1830-supply = < 0x7b >;
		};

		reboot-mode {
			compatible = "syscon-reboot-mode";
			offset = < 0x300 >;
			mode-bootloader = < 0x5242c301 >;
			mode-charge = < 0x5242c30b >;
			mode-fastboot = < 0x5242c309 >;
			mode-loader = < 0x5242c301 >;
			mode-normal = < 0x5242c300 >;
			mode-recovery = < 0x5242c303 >;
			mode-ums = < 0x5242c30c >;
		};

		pmu-pvtm {
			compatible = "rockchip,rk3399-pmu-pvtm";
			clocks = < 0x2f 0x07 >;
			clock-names = "pmu";
			resets = < 0x08 0x1b >;
			reset-names = "pmu";
			status = "disabled";
		};
	};

	spi@ff350000 {
		compatible = "rockchip,rk3399-spi\0rockchip,rk3066-spi";
		reg = < 0x00 0xff350000 0x00 0x1000 >;
		clocks = < 0x2f 0x03 0x2f 0x1f >;
		clock-names = "spiclk\0apb_pclk";
		interrupts = < 0x00 0x3c 0x04 0x00 >;
		pinctrl-names = "default";
		pinctrl-0 = < 0x7c 0x7d 0x7e 0x7f >;
		#address-cells = < 0x01 >;
		#size-cells = < 0x00 >;
		status = "disabled";
	};

	serial@ff370000 {
		compatible = "rockchip,rk3399-uart\0snps,dw-apb-uart";
		reg = < 0x00 0xff370000 0x00 0x100 >;
		clocks = < 0x2f 0x06 0x2f 0x22 >;
		clock-names = "baudclk\0apb_pclk";
		interrupts = < 0x00 0x66 0x04 0x00 >;
		reg-shift = < 0x02 >;
		reg-io-width = < 0x04 >;
		pinctrl-names = "default";
		pinctrl-0 = < 0x80 >;
		status = "disabled";
		assigned-clocks = < 0x2f 0x0c >;
		assigned-clock-parents = < 0x2f 0x01 >;
	};

	i2c@ff3d0000 {
		compatible = "rockchip,rk3399-i2c";
		reg = < 0x00 0xff3d0000 0x00 0x1000 >;
		clocks = < 0x2f 0x0a 0x2f 0x1c >;
		clock-names = "i2c\0pclk";
		interrupts = < 0x00 0x38 0x04 0x00 >;
		pinctrl-names = "default";
		pinctrl-0 = < 0x81 >;
		#address-cells = < 0x01 >;
		#size-cells = < 0x00 >;
		status = "okay";
		i2c-scl-rising-time-ns = < 0x258 >;
		i2c-scl-falling-time-ns = < 0x14 >;

		fusb30x@22 {
			compatible = "fairchild,fusb302";
			reg = < 0x22 >;
			pinctrl-names = "default";
			pinctrl-0 = < 0x82 >;
			int-n-gpios = < 0x33 0x02 0x00 >;
			status = "okay";
			linux,phandle = < 0x27 >;
			phandle = < 0x27 >;
		};

		mpu6500@68 {
			status = "okay";
			compatible = "invensense,mpu6500";
			reg = < 0x68 >;
			irq-gpio = < 0x33 0x00 0x01 >;
			mpu-int_config = < 0x10 >;
			mpu-level_shifter = < 0x00 >;
			mpu-orientation = < 0x00 0x01 0x00 0x01 0x00 0x00 0x00 0x00 0x01 >;
			orientation-x = < 0x01 >;
			orientation-y = < 0x00 >;
			orientation-z = < 0x00 >;
			mpu-debug = < 0x01 >;
		};
	};

	i2c@ff3e0000 {
		compatible = "rockchip,rk3399-i2c";
		reg = < 0x00 0xff3e0000 0x00 0x1000 >;
		clocks = < 0x2f 0x0b 0x2f 0x1d >;
		clock-names = "i2c\0pclk";
		interrupts = < 0x00 0x3a 0x04 0x00 >;
		pinctrl-names = "default";
		pinctrl-0 = < 0x83 >;
		#address-cells = < 0x01 >;
		#size-cells = < 0x00 >;
		status = "disabled";
	};

	phy@e220 {
		compatible = "rockchip,rk3399-pcie-phy";
		#phy-cells = < 0x00 >;
		rockchip,grf = < 0x15 >;
		clocks = < 0x08 0x8a >;
		clock-names = "refclk";
		resets = < 0x08 0x87 >;
		reset-names = "phy";
		status = "okay";
		linux,phandle = < 0x86 >;
		phandle = < 0x86 >;
	};

	pcie@f8000000 {
		compatible = "rockchip,rk3399-pcie";
		#address-cells = < 0x03 >;
		#size-cells = < 0x02 >;
		aspm-no-l0s;
		clocks = < 0x08 0xc5 0x08 0xc4 0x08 0x147 0x08 0xa0 >;
		clock-names = "aclk\0aclk-perf\0hclk\0pm";
		bus-range = < 0x00 0x01 >;
		max-link-speed = < 0x01 >;
		linux,pci-domain = < 0x00 >;
		msi-map = < 0x00 0x84 0x00 0x1000 >;
		interrupts = < 0x00 0x31 0x04 0x00 0x00 0x32 0x04 0x00 0x00 0x33 0x04 0x00 >;
		interrupt-names = "sys\0legacy\0client";
		#interrupt-cells = < 0x01 >;
		interrupt-map-mask = < 0x00 0x00 0x00 0x07 >;
		interrupt-map = < 0x00 0x00 0x00 0x01 0x85 0x00 0x00 0x00 0x00 0x02 0x85 0x01 0x00 0x00 0x00 0x03 0x85 0x02 0x00 0x00 0x00 0x04 0x85 0x03 >;
		phys = < 0x86 >;
		phy-names = "pcie-phy";
		ranges = < 0x82000000 0x00 0xfa000000 0x00 0xfa000000 0x00 0x600000 0x81000000 0x00 0xfa600000 0x00 0xfa600000 0x00 0x100000 >;
		reg = < 0x00 0xf8000000 0x00 0x2000000 0x00 0xfd000000 0x00 0x1000000 >;
		reg-names = "axi-base\0apb-base";
		resets = < 0x08 0x82 0x08 0x83 0x08 0x84 0x08 0x85 0x08 0x86 0x08 0x81 0x08 0x80 >;
		reset-names = "core\0mgmt\0mgmt-sticky\0pipe\0pm\0pclk\0aclk";
		status = "okay";
		assigned-clocks = < 0x08 0x8a >;
		assigned-clock-parents = < 0x08 0xa7 >;
		assigned-clock-rates = < 0x5f5e100 >;
		ep-gpios = < 0x87 0x04 0x00 >;
		num-lanes = < 0x04 >;
		pinctrl-names = "default";
		pinctrl-0 = < 0x88 >;

		interrupt-controller {
			interrupt-controller;
			#address-cells = < 0x00 >;
			#interrupt-cells = < 0x01 >;
			linux,phandle = < 0x85 >;
			phandle = < 0x85 >;
		};
	};

	pwm@ff420000 {
		compatible = "rockchip,rk3399-pwm\0rockchip,rk3288-pwm";
		reg = < 0x00 0xff420000 0x00 0x10 >;
		#pwm-cells = < 0x03 >;
		pinctrl-names = "default";
		pinctrl-0 = < 0x89 >;
		clocks = < 0x2f 0x1e >;
		clock-names = "pwm";
		status = "okay";
		linux,phandle = < 0xc5 >;
		phandle = < 0xc5 >;
	};

	pwm@ff420010 {
		compatible = "rockchip,rk3399-pwm\0rockchip,rk3288-pwm";
		reg = < 0x00 0xff420010 0x00 0x10 >;
		#pwm-cells = < 0x03 >;
		pinctrl-names = "default";
		pinctrl-0 = < 0x8a >;
		clocks = < 0x2f 0x1e >;
		clock-names = "pwm";
		status = "disabled";
	};

	pwm@ff420020 {
		compatible = "rockchip,rk3399-pwm\0rockchip,rk3288-pwm";
		reg = < 0x00 0xff420020 0x00 0x10 >;
		#pwm-cells = < 0x03 >;
		pinctrl-names = "default";
		pinctrl-0 = < 0x8b >;
		clocks = < 0x2f 0x1e >;
		clock-names = "pwm";
		status = "okay";
		linux,phandle = < 0xcb >;
		phandle = < 0xcb >;
	};

	pwm@ff420030 {
		compatible = "rockchip,rk3399-pwm\0rockchip,rk3288-pwm";
		reg = < 0x00 0xff420030 0x00 0x10 >;
		#pwm-cells = < 0x03 >;
		pinctrl-names = "default";
		pinctrl-0 = < 0x8c >;
		clocks = < 0x2f 0x1e >;
		clock-names = "pwm";
		status = "disabled";
	};

	dfi@ff630000 {
		reg = < 0x00 0xff630000 0x00 0x4000 >;
		compatible = "rockchip,rk3399-dfi";
		rockchip,pmu = < 0x8d >;
		clocks = < 0x08 0x179 >;
		clock-names = "pclk_ddr_mon";
		status = "disabled";
		linux,phandle = < 0x8e >;
		phandle = < 0x8e >;
	};

	dmc {
		compatible = "rockchip,rk3399-dmc";
		devfreq-events = < 0x8e >;
		interrupts = < 0x00 0x01 0x04 0x00 >;
		clocks = < 0x08 0xaa >;
		clock-names = "dmc_clk";
		ddr_timing = < 0x8f >;
		upthreshold = < 0x28 >;
		downdifferential = < 0x14 >;
		system-status-freq = < 0x01 0xc3500 0x08 0x80e80 0x02 0x30d40 0x20 0x493e0 0x10 0x927c0 0x10000 0xc3500 0x2000 0xc3500 0x1000 0x61a80 0xc00 0x927c0 0x4000 0x927c0 >;
		auto-min-freq = < 0x61a80 >;
		auto-freq-en = < 0x01 >;
		status = "disabled";
		operating-points-v2 = < 0x90 >;
	};

	vpu_service@ff650000 {
		compatible = "rockchip,vpu_service";
		rockchip,grf = < 0x15 >;
		iommus = < 0x91 >;
		iommu_enabled = < 0x01 >;
		reg = < 0x00 0xff650000 0x00 0x800 >;
		interrupts = < 0x00 0x71 0x04 0x00 0x00 0x72 0x04 0x00 >;
		interrupt-names = "irq_dec\0irq_enc";
		clocks = < 0x08 0xeb 0x08 0x1ea >;
		clock-names = "aclk_vcodec\0hclk_vcodec";
		resets = < 0x08 0x53 0x08 0x51 >;
		reset-names = "video_h\0video_a";
		power-domains = < 0x16 0x1f >;
		dev_mode = < 0x00 >;
		allocator = < 0x01 >;
		status = "okay";
	};

	iommu@ff650800 {
		compatible = "rockchip,iommu";
		reg = < 0x00 0xff650800 0x00 0x40 >;
		interrupts = < 0x00 0x73 0x04 0x00 >;
		interrupt-names = "vpu_mmu";
		clocks = < 0x08 0xeb 0x08 0x1ea >;
		clock-names = "aclk\0hclk";
		power-domains = < 0x16 0x1f >;
		#iommu-cells = < 0x00 >;
		linux,phandle = < 0x91 >;
		phandle = < 0x91 >;
	};

	rkvdec@ff660000 {
		compatible = "rockchip,rkvdec";
		rockchip,grf = < 0x15 >;
		iommus = < 0x92 >;
		iommu_enabled = < 0x01 >;
		reg = < 0x00 0xff660000 0x00 0x400 >;
		interrupts = < 0x00 0x74 0x04 0x00 >;
		interrupt-names = "irq_dec";
		clocks = < 0x08 0xed 0x08 0x1ec 0x08 0x9f 0x08 0x9e >;
		clock-names = "aclk_vcodec\0hclk_vcodec\0clk_cabac\0clk_core";
		resets = < 0x08 0x5b 0x08 0x59 0x08 0x5c 0x08 0x5d 0x08 0x58 0x08 0x5a >;
		reset-names = "video_h\0video_a\0video_core\0video_cabac\0niu_a\0niu_h";
		power-domains = < 0x16 0x20 >;
		dev_mode = < 0x02 >;
		allocator = < 0x01 >;
		status = "okay";
	};

	iommu@ff660480 {
		compatible = "rockchip,iommu";
		reg = < 0x00 0xff660480 0x00 0x40 0x00 0xff6604c0 0x00 0x40 >;
		interrupts = < 0x00 0x75 0x04 0x00 >;
		interrupt-names = "vdec_mmu";
		clocks = < 0x08 0xed 0x08 0x1ec >;
		clock-names = "aclk\0hclk";
		power-domains = < 0x16 0x20 >;
		#iommu-cells = < 0x00 >;
		linux,phandle = < 0x92 >;
		phandle = < 0x92 >;
	};

	iep@ff670000 {
		compatible = "rockchip,iep";
		iommu_enabled = < 0x01 >;
		iommus = < 0x93 >;
		reg = < 0x00 0xff670000 0x00 0x800 >;
		interrupts = < 0x00 0x2a 0x04 0x00 >;
		clocks = < 0x08 0xe1 0x08 0x1dd >;
		clock-names = "aclk_iep\0hclk_iep";
		power-domains = < 0x16 0x22 >;
		allocator = < 0x01 >;
		version = < 0x02 >;
		status = "okay";
	};

	iommu@ff670800 {
		compatible = "rockchip,iommu";
		reg = < 0x00 0xff670800 0x00 0x40 >;
		interrupts = < 0x00 0x2a 0x04 0x00 >;
		interrupt-names = "iep_mmu";
		#iommu-cells = < 0x00 >;
		status = "okay";
		linux,phandle = < 0x93 >;
		phandle = < 0x93 >;
	};

	rga@ff680000 {
		compatible = "rockchip,rga2";
		reg = < 0x00 0xff680000 0x00 0x1000 >;
		interrupts = < 0x00 0x37 0x04 0x00 >;
		clocks = < 0x08 0xdc 0x08 0x1e5 0x08 0x6d >;
		clock-names = "aclk_rga\0hclk_rga\0clk_rga";
		resets = < 0x08 0x6a 0x08 0x67 0x08 0x69 >;
		reset-names = "core\0axi\0ahb";
		power-domains = < 0x16 0x21 >;
		status = "okay";
		dev_mode = < 0x01 >;
		dma-coherent;
	};

	efuse@ff690000 {
		compatible = "rockchip,rk3399-efuse";
		reg = < 0x00 0xff690000 0x00 0x80 >;
		#address-cells = < 0x01 >;
		#size-cells = < 0x01 >;
		clocks = < 0x08 0x17d >;
		clock-names = "pclk_efuse";

		id {
			reg = < 0x07 0x10 >;
			linux,phandle = < 0xd2 >;
			phandle = < 0xd2 >;
		};

		cpul-leakage {
			reg = < 0x1a 0x01 >;
			linux,phandle = < 0xc2 >;
			phandle = < 0xc2 >;
		};

		cpub-leakage {
			reg = < 0x17 0x01 >;
			linux,phandle = < 0xc3 >;
			phandle = < 0xc3 >;
		};

		gpu-leakage {
			reg = < 0x18 0x01 >;
			linux,phandle = < 0xc4 >;
			phandle = < 0xc4 >;
		};

		center-leakage {
			reg = < 0x19 0x01 >;
		};

		logic-leakage {
			reg = < 0x1b 0x01 >;
		};

		wafer-info {
			reg = < 0x1c 0x01 >;
		};
	};

	pmu-clock-controller@ff750000 {
		compatible = "rockchip,rk3399-pmucru";
		reg = < 0x00 0xff750000 0x00 0x1000 >;
		#clock-cells = < 0x01 >;
		#reset-cells = < 0x01 >;
		assigned-clocks = < 0x2f 0x01 >;
		assigned-clock-rates = < 0x284af100 >;
		linux,phandle = < 0x2f >;
		phandle = < 0x2f >;
	};

	clock-controller@ff760000 {
		compatible = "rockchip,rk3399-cru";
		reg = < 0x00 0xff760000 0x00 0x1000 >;
		#clock-cells = < 0x01 >;
		#reset-cells = < 0x01 >;
		assigned-clocks = < 0x08 0xc0 0x08 0xc2 0x08 0x1c2 0x08 0x4c 0x08 0xf0 0x08 0xcd 0x08 0x1cd 0x08 0x9f 0x08 0x9e 0x08 0xf4 0x08 0xbe 0x08 0xc9 0x08 0x186 0x08 0xd5 0x08 0x88 0x08 0x87 0x08 0x08 0x08 0x09 0x08 0x06 0x08 0xd0 0x08 0x05 0x08 0xc0 0x08 0x1c0 0x08 0x140 0x08 0xc2 0x08 0x1c1 0x08 0x142 0x08 0x1c2 0x08 0x143 0x08 0x41 0x08 0x42 0x08 0x43 0x08 0x44 0x08 0x45 0x08 0x46 0x08 0x47 0x08 0x48 0x08 0x49 0x08 0x4a 0x08 0x4b 0x08 0xfa 0x08 0xe5 0x08 0xe6 0x08 0x6b 0x08 0x6c 0x08 0x16a 0x08 0xde 0x08 0xe3 0x08 0x1cd 0x08 0x85 0x08 0x86 0x08 0x4e 0x08 0xf0 0x08 0xcd 0x08 0xe1 0x08 0xdc 0x08 0x6d 0x08 0xed 0x08 0xeb 0x08 0x178 0x08 0xd5 0x08 0x9f 0x08 0x9e 0x08 0xf4 0x08 0xbe 0x08 0xc9 0x08 0x186 0x08 0x88 0x08 0x87 0x08 0xd9 0x08 0x1d9 0x08 0xdb 0x08 0x1db >;
		assigned-clock-rates = < 0x47868c0 0x2faf080 0x2faf080 0x2faf080 0x2faf080 0x5f5e100 0x2faf080 0x8f0d180 0x8f0d180 0x8f0d180 0x2faf080 0x8f0d180 0x2faf080 0x5f5e100 0x47868c0 0x47868c0 0x30a32c00 0x30a32c00 0x23c34600 0xbebc200 0x2faf0800 0x8f0d180 0x47868c0 0x23c3460 0x5f5e100 0x5f5e100 0x2faf080 0x5f5e100 0x2faf080 0x5f5e100 0x5f5e100 0x5f5e100 0x5f5e100 0x5f5e100 0x5f5e100 0x2faf080 0x2faf080 0x2faf080 0x2faf080 0x2faf080 0xbebc200 0x17d78400 0x17d78400 0x5f5e100 0x5f5e100 0x5f5e100 0x17d78400 0x17d78400 0xbebc200 0x5f5e100 0xbebc200 0xbebc200 0x5f5e100 0x17d78400 0x17d78400 0x17d78400 0x17d78400 0x11e1a300 0x17d78400 0xbebc200 0x17d78400 0x11e1a300 0x11e1a300 0x11e1a300 0x11e1a300 0x11e1a300 0x5f5e100 0x8f0d180 0x8f0d180 0x17d78400 0x5f5e100 0x17d78400 0x5f5e100 >;
		linux,phandle = < 0x08 >;
		phandle = < 0x08 >;
	};

	syscon@ff770000 {
		compatible = "rockchip,rk3399-grf\0syscon\0simple-mfd";
		reg = < 0x00 0xff770000 0x00 0x10000 >;
		#address-cells = < 0x01 >;
		#size-cells = < 0x01 >;
		linux,phandle = < 0x15 >;
		phandle = < 0x15 >;

		io-domains {
			compatible = "rockchip,rk3399-io-voltage-domain";
			status = "okay";
			bt656-supply = < 0x94 >;
			audio-supply = < 0x95 >;
			sdmmc-supply = < 0x1f >;
			gpio1830-supply = < 0x7b >;
		};

		phy@f780 {
			compatible = "rockchip,rk3399-emmc-phy";
			reg = < 0xf780 0x24 >;
			clocks = < 0x96 >;
			clock-names = "emmcclk";
			#phy-cells = < 0x00 >;
			status = "okay";
			linux,phandle = < 0x24 >;
			phandle = < 0x24 >;
		};

		usb2-phy@e450 {
			compatible = "rockchip,rk3399-usb2phy";
			reg = < 0xe450 0x10 >;
			clocks = < 0x08 0x7b >;
			clock-names = "phyclk";
			#clock-cells = < 0x00 >;
			clock-output-names = "clk_usbphy0_480m";
			status = "okay";
			extcon = < 0x27 >;

			otg-port {
				#phy-cells = < 0x00 >;
				interrupts = < 0x00 0x67 0x04 0x00 0x00 0x68 0x04 0x00 0x00 0x6a 0x04 0x00 >;
				interrupt-names = "otg-bvalid\0otg-id\0linestate";
				status = "okay";
				linux,phandle = < 0x28 >;
				phandle = < 0x28 >;
			};

			host-port {
				#phy-cells = < 0x00 >;
				interrupts = < 0x00 0x1b 0x04 0x00 >;
				interrupt-names = "linestate";
				status = "okay";
				phy-supply = < 0x97 >;
				linux,phandle = < 0x25 >;
				phandle = < 0x25 >;
			};
		};

		usb2-phy@e460 {
			compatible = "rockchip,rk3399-usb2phy";
			reg = < 0xe460 0x10 >;
			clocks = < 0x08 0x7c >;
			clock-names = "phyclk";
			#clock-cells = < 0x00 >;
			clock-output-names = "clk_usbphy1_480m";
			status = "okay";

			otg-port {
				#phy-cells = < 0x00 >;
				interrupts = < 0x00 0x6c 0x04 0x00 0x00 0x6d 0x04 0x00 0x00 0x6f 0x04 0x00 >;
				interrupt-names = "otg-bvalid\0otg-id\0linestate";
				status = "okay";
				linux,phandle = < 0x2a >;
				phandle = < 0x2a >;
			};

			host-port {
				#phy-cells = < 0x00 >;
				interrupts = < 0x00 0x1f 0x04 0x00 >;
				interrupt-names = "linestate";
				status = "okay";
				phy-supply = < 0x97 >;
				linux,phandle = < 0x26 >;
				phandle = < 0x26 >;
			};
		};

		pvtm {
			compatible = "rockchip,rk3399-pvtm";
			clocks = < 0x08 0x73 0x08 0x74 0x08 0x75 0x08 0x76 >;
			clock-names = "core_l\0core_b\0gpu\0ddr";
			resets = < 0x08 0x1f 0x08 0x2f 0x08 0x123 0x08 0x4f >;
			reset-names = "core_l\0core_b\0gpu\0ddr";
			status = "okay";
		};
	};

	phy@ff7c0000 {
		compatible = "rockchip,rk3399-typec-phy";
		reg = < 0x00 0xff7c0000 0x00 0x40000 >;
		rockchip,grf = < 0x15 >;
		#phy-cells = < 0x01 >;
		clocks = < 0x08 0x7e 0x08 0x7d >;
		clock-names = "tcpdcore\0tcpdphy-ref";
		assigned-clocks = < 0x08 0x7e >;
		assigned-clock-rates = < 0x2faf080 >;
		power-domains = < 0x16 0x08 >;
		resets = < 0x08 0x95 0x08 0x94 0x08 0x14c >;
		reset-names = "uphy\0uphy-pipe\0uphy-tcphy";
		rockchip,typec-conn-dir = < 0xe580 0x00 0x10 >;
		rockchip,usb3tousb2-en = < 0xe580 0x03 0x13 >;
		rockchip,usb3-host-disable = < 0x2434 0x00 0x10 >;
		rockchip,usb3-host-port = < 0x2434 0x0c 0x1c >;
		rockchip,external-psm = < 0xe588 0x0e 0x1e >;
		rockchip,pipe-status = < 0xe5c0 0x00 0x00 >;
		rockchip,uphy-dp-sel = < 0x6268 0x13 0x13 >;
		status = "okay";
		extcon = < 0x27 >;

		dp-port {
			#phy-cells = < 0x00 >;
			linux,phandle = < 0x2c >;
			phandle = < 0x2c >;
		};

		usb3-port {
			#phy-cells = < 0x00 >;
			linux,phandle = < 0x29 >;
			phandle = < 0x29 >;
		};
	};

	phy@ff800000 {
		compatible = "rockchip,rk3399-typec-phy";
		reg = < 0x00 0xff800000 0x00 0x40000 >;
		rockchip,grf = < 0x15 >;
		#phy-cells = < 0x01 >;
		clocks = < 0x08 0x80 0x08 0x7f >;
		clock-names = "tcpdcore\0tcpdphy-ref";
		assigned-clocks = < 0x08 0x80 >;
		assigned-clock-rates = < 0x2faf080 >;
		power-domains = < 0x16 0x09 >;
		resets = < 0x08 0x9d 0x08 0x9c 0x08 0x14d >;
		reset-names = "uphy\0uphy-pipe\0uphy-tcphy";
		rockchip,typec-conn-dir = < 0xe58c 0x00 0x10 >;
		rockchip,usb3tousb2-en = < 0xe58c 0x03 0x13 >;
		rockchip,usb3-host-disable = < 0x2444 0x00 0x10 >;
		rockchip,usb3-host-port = < 0x2444 0x0c 0x1c >;
		rockchip,external-psm = < 0xe594 0x0e 0x1e >;
		rockchip,pipe-status = < 0xe5c0 0x10 0x10 >;
		rockchip,uphy-dp-sel = < 0x6268 0x03 0x13 >;
		status = "okay";

		dp-port {
			#phy-cells = < 0x00 >;
		};

		usb3-port {
			#phy-cells = < 0x00 >;
			linux,phandle = < 0x2b >;
			phandle = < 0x2b >;
		};
	};

	watchdog@ff848000 {
		compatible = "snps,dw-wdt";
		reg = < 0x00 0xff848000 0x00 0x100 >;
		clocks = < 0x08 0x17c >;
		interrupts = < 0x00 0x78 0x04 0x00 >;
	};

	rktimer@ff850000 {
		compatible = "rockchip,rk3399-timer";
		reg = < 0x00 0xff850000 0x00 0x1000 >;
		interrupts = < 0x00 0x51 0x04 0x00 >;
		clocks = < 0x08 0x168 0x08 0x5a >;
		clock-names = "pclk\0timer";
	};

	spdif@ff870000 {
		compatible = "rockchip,rk3399-spdif";
		reg = < 0x00 0xff870000 0x00 0x1000 >;
		interrupts = < 0x00 0x42 0x04 0x00 >;
		dmas = < 0x98 0x07 >;
		dma-names = "tx";
		clock-names = "mclk\0hclk";
		clocks = < 0x08 0x55 0x08 0x1d7 >;
		pinctrl-names = "default";
		pinctrl-0 = < 0x99 >;
		power-domains = < 0x16 0x1c >;
		status = "okay";
		i2c-scl-rising-time-ns = < 0x1c2 >;
		i2c-scl-falling-time-ns = < 0x0f >;
		#sound-dai-cells = < 0x00 >;
		assigned-clocks = < 0x08 0xb1 >;
		assigned-clock-parents = < 0x08 0x05 >;
		linux,phandle = < 0xce >;
		phandle = < 0xce >;
	};

	i2s@ff880000 {
		compatible = "rockchip,rk3399-i2s\0rockchip,rk3066-i2s";
		reg = < 0x00 0xff880000 0x00 0x1000 >;
		rockchip,grf = < 0x15 >;
		interrupts = < 0x00 0x27 0x04 0x00 >;
		dmas = < 0x98 0x00 0x98 0x01 >;
		dma-names = "tx\0rx";
		clock-names = "i2s_clk\0i2s_hclk";
		clocks = < 0x08 0x56 0x08 0x1d4 >;
		pinctrl-names = "default";
		pinctrl-0 = < 0x9a >;
		power-domains = < 0x16 0x1c >;
		status = "okay";
		rockchip,i2s-broken-burst-len;
		rockchip,playback-channels = < 0x08 >;
		rockchip,capture-channels = < 0x08 >;
		#sound-dai-cells = < 0x00 >;
		assigned-clocks = < 0x08 0xae >;
		assigned-clock-parents = < 0x08 0x05 >;
		linux,phandle = < 0xcc >;
		phandle = < 0xcc >;
	};

	i2s@ff890000 {
		compatible = "rockchip,rk3399-i2s\0rockchip,rk3066-i2s";
		reg = < 0x00 0xff890000 0x00 0x1000 >;
		interrupts = < 0x00 0x28 0x04 0x00 >;
		dmas = < 0x98 0x02 0x98 0x03 >;
		dma-names = "tx\0rx";
		clock-names = "i2s_clk\0i2s_hclk";
		clocks = < 0x08 0x57 0x08 0x1d5 >;
		pinctrl-names = "default";
		pinctrl-0 = < 0x9b >;
		power-domains = < 0x16 0x1c >;
		status = "disabled";
		assigned-clocks = < 0x08 0xaf >;
		assigned-clock-parents = < 0x08 0x05 >;
	};

	i2s@ff8a0000 {
		compatible = "rockchip,rk3399-i2s\0rockchip,rk3066-i2s";
		reg = < 0x00 0xff8a0000 0x00 0x1000 >;
		interrupts = < 0x00 0x29 0x04 0x00 >;
		dmas = < 0x98 0x04 0x98 0x05 >;
		dma-names = "tx\0rx";
		clock-names = "i2s_clk\0i2s_hclk";
		clocks = < 0x08 0x58 0x08 0x1d6 >;
		power-domains = < 0x16 0x1c >;
		status = "okay";
		#sound-dai-cells = < 0x00 >;
		assigned-clocks = < 0x08 0xb0 >;
		assigned-clock-parents = < 0x08 0x05 >;
		rockchip,bclk-fs = < 0x80 >;
		linux,phandle = < 0xc6 >;
		phandle = < 0xc6 >;
	};

	gpu@ff9a0000 {
		compatible = "arm,malit860\0arm,malit86x\0arm,malit8xx\0arm,mali-midgard";
		reg = < 0x00 0xff9a0000 0x00 0x10000 >;
		interrupts = < 0x00 0x13 0x04 0x00 0x00 0x14 0x04 0x00 0x00 0x15 0x04 0x00 >;
		interrupt-names = "GPU\0JOB\0MMU";
		clocks = < 0x08 0xd0 >;
		clock-names = "clk_mali";
		#cooling-cells = < 0x02 >;
		power-domains = < 0x16 0x23 >;
		power-off-delay-ms = < 0xc8 >;
		status = "okay";
		operating-points-v2 = < 0x9c >;
		mali-supply = < 0x9d >;
		linux,phandle = < 0x5f >;
		phandle = < 0x5f >;

		power_model {
			compatible = "arm,mali-simple-power-model";
			voltage = < 0x384 >;
			frequency = < 0x1f4 >;
			static-power = < 0x12c >;
			dynamic-power = < 0x18c >;
			ts = < 0x7d00 0x125c 0xffffffb0 0x02 >;
			thermal-zone = "gpu-thermal";
		};
	};

	vop@ff8f0000 {
		compatible = "rockchip,rk3399-vop-lit";
		reg = < 0x00 0xff8f0000 0x00 0x600 0x00 0xff8f1c00 0x00 0x200 0x00 0xff8f2000 0x00 0x400 >;
		reg-names = "regs\0cabc_lut\0gamma_lut";
		interrupts = < 0x00 0x77 0x04 0x00 >;
		clocks = < 0x08 0xdb 0x08 0xb5 0x08 0x1db 0x08 0xb7 >;
		clock-names = "aclk_vop\0dclk_vop\0hclk_vop\0dclk_source";
		resets = < 0x08 0x113 0x08 0x117 0x08 0x119 >;
		reset-names = "axi\0ahb\0dclk";
		power-domains = < 0x16 0x12 >;
		iommus = < 0x9e >;
		status = "okay";

		port {
			#address-cells = < 0x01 >;
			#size-cells = < 0x00 >;
			linux,phandle = < 0xba >;
			phandle = < 0xba >;

			endpoint@0 {
				reg = < 0x00 >;
				remote-endpoint = < 0x9f >;
				linux,phandle = < 0xb0 >;
				phandle = < 0xb0 >;
			};

			endpoint@1 {
				reg = < 0x01 >;
				remote-endpoint = < 0xa0 >;
				linux,phandle = < 0xb8 >;
				phandle = < 0xb8 >;
			};

			endpoint@2 {
				reg = < 0x02 >;
				remote-endpoint = < 0xa1 >;
				linux,phandle = < 0xae >;
				phandle = < 0xae >;
			};

			endpoint@3 {
				reg = < 0x03 >;
				remote-endpoint = < 0xa2 >;
				linux,phandle = < 0x2e >;
				phandle = < 0x2e >;
			};

			endpoint@4 {
				reg = < 0x04 >;
				remote-endpoint = < 0xa3 >;
				linux,phandle = < 0xb5 >;
				phandle = < 0xb5 >;
			};
		};
	};

	voppwm@ff8f01a0 {
		compatible = "rockchip,vop-pwm";
		reg = < 0x00 0xff8f01a0 0x00 0x10 >;
		#pwm-cells = < 0x03 >;
		pinctrl-names = "default";
		pinctrl-0 = < 0xa4 >;
		clocks = < 0x08 0x6c >;
		clock-names = "pwm";
		status = "disabled";
	};

	iommu@ff8f3f00 {
		compatible = "rockchip,iommu";
		reg = < 0x00 0xff8f3f00 0x00 0x100 >;
		interrupts = < 0x00 0x77 0x04 0x00 >;
		interrupt-names = "vopl_mmu";
		clocks = < 0x08 0xdb 0x08 0x1db >;
		clock-names = "aclk\0hclk";
		power-domains = < 0x16 0x12 >;
		#iommu-cells = < 0x00 >;
		status = "okay";
		linux,phandle = < 0x9e >;
		phandle = < 0x9e >;
	};

	vop@ff900000 {
		compatible = "rockchip,rk3399-vop-big";
		reg = < 0x00 0xff900000 0x00 0x600 0x00 0xff901c00 0x00 0x200 0x00 0xff902000 0x00 0x1000 >;
		reg-names = "regs\0cabc_lut\0gamma_lut";
		interrupts = < 0x00 0x76 0x04 0x00 >;
		clocks = < 0x08 0xd9 0x08 0xb4 0x08 0x1d9 0x08 0xb6 >;
		clock-names = "aclk_vop\0dclk_vop\0hclk_vop\0dclk_source";
		resets = < 0x08 0x112 0x08 0x116 0x08 0x118 >;
		reset-names = "axi\0ahb\0dclk";
		power-domains = < 0x16 0x11 >;
		iommus = < 0xa5 >;
		status = "okay";

		port {
			#address-cells = < 0x01 >;
			#size-cells = < 0x00 >;
			linux,phandle = < 0xb9 >;
			phandle = < 0xb9 >;

			endpoint@0 {
				reg = < 0x00 >;
				remote-endpoint = < 0xa6 >;
				linux,phandle = < 0xb7 >;
				phandle = < 0xb7 >;
			};

			endpoint@1 {
				reg = < 0x01 >;
				remote-endpoint = < 0xa7 >;
				linux,phandle = < 0xaf >;
				phandle = < 0xaf >;
			};

			endpoint@2 {
				reg = < 0x02 >;
				remote-endpoint = < 0xa8 >;
				linux,phandle = < 0xad >;
				phandle = < 0xad >;
			};

			endpoint@3 {
				reg = < 0x03 >;
				remote-endpoint = < 0xa9 >;
				linux,phandle = < 0x2d >;
				phandle = < 0x2d >;
			};

			endpoint@4 {
				reg = < 0x04 >;
				remote-endpoint = < 0xaa >;
				linux,phandle = < 0xb4 >;
				phandle = < 0xb4 >;
			};
		};
	};

	voppwm@ff9001a0 {
		compatible = "rockchip,vop-pwm";
		reg = < 0x00 0xff9001a0 0x00 0x10 >;
		#pwm-cells = < 0x03 >;
		pinctrl-names = "default";
		pinctrl-0 = < 0xab >;
		clocks = < 0x08 0x6b >;
		clock-names = "pwm";
		status = "disabled";
	};

	iommu@ff903f00 {
		compatible = "rockchip,iommu";
		reg = < 0x00 0xff903f00 0x00 0x100 >;
		interrupts = < 0x00 0x76 0x04 0x00 >;
		interrupt-names = "vopb_mmu";
		clocks = < 0x08 0xd9 0x08 0x1d9 >;
		clock-names = "aclk\0hclk";
		power-domains = < 0x16 0x11 >;
		#iommu-cells = < 0x00 >;
		status = "okay";
		linux,phandle = < 0xa5 >;
		phandle = < 0xa5 >;
	};

	iommu@ff914000 {
		compatible = "rockchip,iommu";
		reg = < 0x00 0xff914000 0x00 0x100 0x00 0xff915000 0x00 0x100 >;
		interrupts = < 0x00 0x2b 0x04 0x00 >;
		interrupt-names = "isp0_mmu";
		#iommu-cells = < 0x00 >;
		clocks = < 0x08 0xe7 0x08 0x1e1 >;
		clock-names = "aclk\0hclk";
		power-domains = < 0x16 0x13 >;
		rk_iommu,disable_reset_quirk;
		status = "okay";
		linux,phandle = < 0xda >;
		phandle = < 0xda >;
	};

	iommu@ff924000 {
		compatible = "rockchip,iommu";
		reg = < 0x00 0xff924000 0x00 0x100 0x00 0xff925000 0x00 0x100 >;
		interrupts = < 0x00 0x2c 0x04 0x00 >;
		interrupt-names = "isp1_mmu";
		#iommu-cells = < 0x00 >;
		clocks = < 0x08 0xe8 0x08 0x1e2 >;
		clock-names = "aclk\0hclk";
		power-domains = < 0x16 0x14 >;
		rk_iommu,disable_reset_quirk;
		status = "okay";
		linux,phandle = < 0xdb >;
		phandle = < 0xdb >;
	};

	hdmi@ff940000 {
		compatible = "rockchip,rk3399-dw-hdmi";
		reg = < 0x00 0xff940000 0x00 0x20000 >;
		reg-io-width = < 0x04 >;
		rockchip,grf = < 0x15 >;
		pinctrl-names = "default";
		pinctrl-0 = < 0xac >;
		power-domains = < 0x16 0x15 >;
		interrupts = < 0x00 0x17 0x04 0x00 >;
		clocks = < 0x08 0x174 0x08 0x71 0x08 0x07 0x08 0x16f >;
		clock-names = "iahb\0isfr\0vpll\0grf";
		status = "okay";
		#address-cells = < 0x01 >;
		#size-cells = < 0x00 >;
		#sound-dai-cells = < 0x00 >;
		ddc-i2c-scl-high-time-ns = < 0x2599 >;
		ddc-i2c-scl-low-time-ns = < 0x2710 >;
		linux,phandle = < 0xc7 >;
		phandle = < 0xc7 >;

		ports {

			port {
				#address-cells = < 0x01 >;
				#size-cells = < 0x00 >;

				endpoint@0 {
					reg = < 0x00 >;
					remote-endpoint = < 0xad >;
					status = "disabled";
					linux,phandle = < 0xa8 >;
					phandle = < 0xa8 >;
				};

				endpoint@1 {
					reg = < 0x01 >;
					remote-endpoint = < 0xae >;
					linux,phandle = < 0xa1 >;
					phandle = < 0xa1 >;
				};
			};
		};
	};

	dsi@ff960000 {
		compatible = "rockchip,rk3399-mipi-dsi";
		reg = < 0x00 0xff960000 0x00 0x8000 >;
		interrupts = < 0x00 0x2d 0x04 0x00 >;
		clocks = < 0x08 0xa2 0x08 0x170 0x08 0xa3 >;
		clock-names = "ref\0pclk\0phy_cfg";
		resets = < 0x08 0xfb >;
		reset-names = "apb";
		power-domains = < 0x16 0x0f >;
		rockchip,grf = < 0x15 >;
		#address-cells = < 0x01 >;
		#size-cells = < 0x00 >;
		status = "okay";
		rockchip,lane-rate = < 0x3e8 >;

		ports {

			port {
				#address-cells = < 0x01 >;
				#size-cells = < 0x00 >;

				endpoint@0 {
					reg = < 0x00 >;
					remote-endpoint = < 0xaf >;
					linux,phandle = < 0xa7 >;
					phandle = < 0xa7 >;
				};

				endpoint@1 {
					reg = < 0x01 >;
					remote-endpoint = < 0xb0 >;
					status = "disalbed";
					linux,phandle = < 0x9f >;
					phandle = < 0x9f >;
				};
			};
		};

		panel@0 {
			compatible = "simple-panel-dsi";
			reg = < 0x00 >;
			backlight = < 0xb1 >;
			enable-gpios = < 0x33 0x0d 0x00 >;
			power-supply = < 0xb2 >;
			init-delay-ms = < 0x14 >;
			enable-delay-ms = < 0x14 >;
			disable-delay-ms = < 0x14 >;
			unprepare-delay-ms = < 0x14 >;
			dsi,flags = < 0xa03 >;
			dsi,format = < 0x00 >;
			dsi,lanes = < 0x04 >;
			panel-init-sequence = < 0x5780111 0x5140129 >;
			panel-exit-sequence = < 0x5000128 0x5780110 >;

			display-timings {
				native-mode = < 0xb3 >;

				timing0 {
					clock-frequency = < 0x8a48640 >;
					hactive = < 0x780 >;
					vactive = < 0x4b0 >;
					hback-porch = < 0xa0 >;
					hfront-porch = < 0x18 >;
					vback-porch = < 0x0a >;
					vfront-porch = < 0x10 >;
					hsync-len = < 0x0a >;
					vsync-len = < 0x03 >;
					screen-width = < 0x44 >;
					screen-hight = < 0x78 >;
					hsync-active = < 0x00 >;
					vsync-active = < 0x00 >;
					de-active = < 0x00 >;
					pixelclk-active = < 0x00 >;
					linux,phandle = < 0xb3 >;
					phandle = < 0xb3 >;
				};
			};
		};
	};

	dsi@ff968000 {
		compatible = "rockchip,rk3399-mipi-dsi";
		reg = < 0x00 0xff968000 0x00 0x8000 >;
		interrupts = < 0x00 0x2e 0x04 0x00 >;
		clocks = < 0x08 0xa2 0x08 0x171 0x08 0xa4 >;
		clock-names = "ref\0pclk\0phy_cfg";
		resets = < 0x08 0xfc >;
		reset-names = "apb";
		power-domains = < 0x16 0x0f >;
		rockchip,grf = < 0x15 >;
		#address-cells = < 0x01 >;
		#size-cells = < 0x00 >;
		status = "disabled";

		ports {

			port {
				#address-cells = < 0x01 >;
				#size-cells = < 0x00 >;

				endpoint@0 {
					reg = < 0x00 >;
					remote-endpoint = < 0xb4 >;
					linux,phandle = < 0xaa >;
					phandle = < 0xaa >;
				};

				endpoint@1 {
					reg = < 0x01 >;
					remote-endpoint = < 0xb5 >;
					linux,phandle = < 0xa3 >;
					phandle = < 0xa3 >;
				};
			};
		};
	};

	edp@ff970000 {
		compatible = "rockchip,rk3399-edp";
		reg = < 0x00 0xff970000 0x00 0x8000 >;
		interrupts = < 0x00 0x0a 0x04 0x00 >;
		clocks = < 0x08 0x16a 0x08 0x16c >;
		clock-names = "dp\0pclk";
		power-domains = < 0x16 0x19 >;
		resets = < 0x08 0x11d >;
		reset-names = "dp";
		rockchip,grf = < 0x15 >;
		status = "disabled";
		pinctrl-names = "default";
		pinctrl-0 = < 0xb6 >;

		ports {
			#address-cells = < 0x01 >;
			#size-cells = < 0x00 >;

			port@0 {
				reg = < 0x00 >;
				#address-cells = < 0x01 >;
				#size-cells = < 0x00 >;

				endpoint@0 {
					reg = < 0x00 >;
					remote-endpoint = < 0xb7 >;
					linux,phandle = < 0xa6 >;
					phandle = < 0xa6 >;
				};

				endpoint@1 {
					reg = < 0x01 >;
					remote-endpoint = < 0xb8 >;
					linux,phandle = < 0xa0 >;
					phandle = < 0xa0 >;
				};
			};
		};
	};

	display-subsystem {
		compatible = "rockchip,display-subsystem";
		ports = < 0xb9 0xba >;
		clocks = < 0x08 0x07 0x08 0x04 >;
		clock-names = "hdmi-tmds-pll\0default-vop-pll";
		status = "okay";
		memory-region = < 0xbb >;
		secure-memory-region = < 0xbc >;

		route {

			route-hdmi {
				status = "disabled";
				logo,uboot = "logo.bmp";
				logo,kernel = "logo_kernel.bmp";
				logo,mode = "fullscreen";
				charge_logo,mode = "center";
				connect = < 0xad >;
			};

			route-dsi {
				status = "okay";
				logo,uboot = "logo.bmp";
				logo,kernel = "logo_kernel.bmp";
				logo,mode = "fullscreen";
				charge_logo,mode = "center";
				connect = < 0xaf >;
			};

			route-dsi1 {
				status = "disabled";
				logo,uboot = "logo.bmp";
				logo,kernel = "logo_kernel.bmp";
				logo,mode = "fullscreen";
				charge_logo,mode = "center";
				connect = < 0xb5 >;
			};

			route-edp {
				status = "disabled";
				logo,uboot = "logo.bmp";
				logo,kernel = "logo_kernel.bmp";
				logo,mode = "fullscreen";
				charge_logo,mode = "center";
				connect = < 0xb7 >;
			};
		};
	};

	pinctrl {
		compatible = "rockchip,rk3399-pinctrl";
		rockchip,grf = < 0x15 >;
		rockchip,pmu = < 0x8d >;
		#address-cells = < 0x02 >;
		#size-cells = < 0x02 >;
		ranges;

		gpio0@ff720000 {
			compatible = "rockchip,gpio-bank";
			reg = < 0x00 0xff720000 0x00 0x100 >;
			clocks = < 0x2f 0x17 >;
			interrupts = < 0x00 0x0e 0x04 0x00 >;
			gpio-controller;
			#gpio-cells = < 0x02 >;
			interrupt-controller;
			#interrupt-cells = < 0x02 >;
			linux,phandle = < 0x3b >;
			phandle = < 0x3b >;
		};

		gpio1@ff730000 {
			compatible = "rockchip,gpio-bank";
			reg = < 0x00 0xff730000 0x00 0x100 >;
			clocks = < 0x2f 0x18 >;
			interrupts = < 0x00 0x0f 0x04 0x00 >;
			gpio-controller;
			#gpio-cells = < 0x02 >;
			interrupt-controller;
			#interrupt-cells = < 0x02 >;
			linux,phandle = < 0x33 >;
			phandle = < 0x33 >;
		};

		gpio2@ff780000 {
			compatible = "rockchip,gpio-bank";
			reg = < 0x00 0xff780000 0x00 0x100 >;
			clocks = < 0x08 0x150 >;
			interrupts = < 0x00 0x10 0x04 0x00 >;
			gpio-controller;
			#gpio-cells = < 0x02 >;
			interrupt-controller;
			#interrupt-cells = < 0x02 >;
			linux,phandle = < 0x87 >;
			phandle = < 0x87 >;
		};

		gpio3@ff788000 {
			compatible = "rockchip,gpio-bank";
			reg = < 0x00 0xff788000 0x00 0x100 >;
			clocks = < 0x08 0x151 >;
			interrupts = < 0x00 0x11 0x04 0x00 >;
			gpio-controller;
			#gpio-cells = < 0x02 >;
			interrupt-controller;
			#interrupt-cells = < 0x02 >;
			linux,phandle = < 0x18 >;
			phandle = < 0x18 >;
		};

		gpio4@ff790000 {
			compatible = "rockchip,gpio-bank";
			reg = < 0x00 0xff790000 0x00 0x100 >;
			clocks = < 0x08 0x152 >;
			interrupts = < 0x00 0x12 0x04 0x00 >;
			gpio-controller;
			#gpio-cells = < 0x02 >;
			interrupt-controller;
			#interrupt-cells = < 0x02 >;
			linux,phandle = < 0x3c >;
			phandle = < 0x3c >;
		};

		pcfg-pull-up {
			bias-pull-up;
			linux,phandle = < 0xbd >;
			phandle = < 0xbd >;
		};

		pcfg-pull-down {
			bias-pull-down;
			linux,phandle = < 0xc1 >;
			phandle = < 0xc1 >;
		};

		pcfg-pull-none {
			bias-disable;
			linux,phandle = < 0xbf >;
			phandle = < 0xbf >;
		};

		pcfg-pull-up-20ma {
			bias-pull-up;
			drive-strength = < 0x14 >;
		};

		pcfg-pull-none-20ma {
			bias-disable;
			drive-strength = < 0x14 >;
		};

		pcfg-pull-none-18ma {
			bias-disable;
			drive-strength = < 0x12 >;
		};

		pcfg-pull-none-12ma {
			bias-disable;
			drive-strength = < 0x0c >;
			linux,phandle = < 0xc0 >;
			phandle = < 0xc0 >;
		};

		pcfg-pull-up-8ma {
			bias-pull-up;
			drive-strength = < 0x08 >;
		};

		pcfg-pull-down-4ma {
			bias-pull-down;
			drive-strength = < 0x04 >;
		};

		pcfg-pull-up-2ma {
			bias-pull-up;
			drive-strength = < 0x02 >;
		};

		pcfg-pull-down-12ma {
			bias-pull-down;
			drive-strength = < 0x0c >;
		};

		pcfg-pull-none-13ma {
			bias-disable;
			drive-strength = < 0x0d >;
			linux,phandle = < 0xbe >;
			phandle = < 0xbe >;
		};

		pcfg-output-high {
			output-high;
		};

		pcfg-output-low {
			output-low;
		};

		pcfg-input {
			input-enable;
		};

		emmc {

			emmc-pwr {
				rockchip,pins = < 0x00 0x05 0x01 0xbd >;
			};
		};

		gmac {

			rgmii-pins {
				rockchip,pins = < 0x03 0x11 0x01 0xbe 0x03 0x0e 0x01 0xbf 0x03 0x0d 0x01 0xbf 0x03 0x0c 0x01 0xbe 0x03 0x0b 0x01 0xbf 0x03 0x09 0x01 0xbf 0x03 0x08 0x01 0xbf 0x03 0x07 0x01 0xbf 0x03 0x06 0x01 0xbf 0x03 0x05 0x01 0xbe 0x03 0x04 0x01 0xbe 0x03 0x03 0x01 0xbf 0x03 0x02 0x01 0xbf 0x03 0x01 0x01 0xbe 0x03 0x00 0x01 0xbe >;
				linux,phandle = < 0x1a >;
				phandle = < 0x1a >;
			};

			rmii-pins {
				rockchip,pins = < 0x03 0x0d 0x01 0xbf 0x03 0x0c 0x01 0xbe 0x03 0x0b 0x01 0xbf 0x03 0x0a 0x01 0xbf 0x03 0x09 0x01 0xbf 0x03 0x08 0x01 0xbf 0x03 0x07 0x01 0xbf 0x03 0x06 0x01 0xbf 0x03 0x05 0x01 0xbe 0x03 0x04 0x01 0xbe >;
			};
		};

		i2c0 {

			i2c0-xfer {
				rockchip,pins = < 0x01 0x0f 0x02 0xbf 0x01 0x10 0x02 0xbf >;
				linux,phandle = < 0x30 >;
				phandle = < 0x30 >;
			};
		};

		i2c1 {

			i2c1-xfer {
				rockchip,pins = < 0x04 0x02 0x01 0xbf 0x04 0x01 0x01 0xbf >;
				linux,phandle = < 0x39 >;
				phandle = < 0x39 >;
			};
		};

		i2c2 {

			i2c2-xfer {
				rockchip,pins = < 0x02 0x01 0x02 0xc0 0x02 0x00 0x02 0xc0 >;
				linux,phandle = < 0x3d >;
				phandle = < 0x3d >;
			};
		};

		i2c3 {

			i2c3-xfer {
				rockchip,pins = < 0x04 0x11 0x01 0xbf 0x04 0x10 0x01 0xbf >;
				linux,phandle = < 0x3e >;
				phandle = < 0x3e >;
			};

			i2c3_gpio {
				rockchip,pins = < 0x04 0x11 0x00 0xbf 0x04 0x10 0x00 0xbf >;
			};
		};

		i2c4 {

			i2c4-xfer {
				rockchip,pins = < 0x01 0x0c 0x01 0xbf 0x01 0x0b 0x01 0xbf >;
				linux,phandle = < 0x81 >;
				phandle = < 0x81 >;
			};
		};

		i2c5 {

			i2c5-xfer {
				rockchip,pins = < 0x03 0x0b 0x02 0xbf 0x03 0x0a 0x02 0xbf >;
				linux,phandle = < 0x3f >;
				phandle = < 0x3f >;
			};
		};

		i2c6 {

			i2c6-xfer {
				rockchip,pins = < 0x02 0x0a 0x02 0xbf 0x02 0x09 0x02 0xbf >;
				linux,phandle = < 0x40 >;
				phandle = < 0x40 >;
			};
		};

		i2c7 {

			i2c7-xfer {
				rockchip,pins = < 0x02 0x08 0x02 0xbf 0x02 0x07 0x02 0xbf >;
				linux,phandle = < 0x41 >;
				phandle = < 0x41 >;
			};
		};

		i2c8 {

			i2c8-xfer {
				rockchip,pins = < 0x01 0x15 0x01 0xbf 0x01 0x14 0x01 0xbf >;
				linux,phandle = < 0x83 >;
				phandle = < 0x83 >;
			};
		};

		i2s0 {

			i2s0-8ch-bus {
				rockchip,pins = < 0x03 0x18 0x01 0xbf 0x03 0x19 0x01 0xbf 0x03 0x1a 0x01 0xbf 0x03 0x1b 0x01 0xbf 0x03 0x1c 0x01 0xbf 0x03 0x1d 0x01 0xbf 0x03 0x1e 0x01 0xbf 0x03 0x1f 0x01 0xbf >;
				linux,phandle = < 0x9a >;
				phandle = < 0x9a >;
			};

			i2s-8ch-mclk {
				rockchip,pins = < 0x04 0x00 0x01 0xbf >;
				linux,phandle = < 0x3a >;
				phandle = < 0x3a >;
			};
		};

		i2s1 {

			i2s1-2ch-bus {
				rockchip,pins = < 0x04 0x03 0x01 0xbf 0x04 0x04 0x01 0xbf 0x04 0x05 0x01 0xbf 0x04 0x06 0x01 0xbf 0x04 0x07 0x01 0xbf >;
				linux,phandle = < 0x9b >;
				phandle = < 0x9b >;
			};
		};

		sdio0 {

			sdio0-bus1 {
				rockchip,pins = < 0x02 0x14 0x01 0xbd >;
			};

			sdio0-bus4 {
				rockchip,pins = < 0x02 0x14 0x01 0xbd 0x02 0x15 0x01 0xbd 0x02 0x16 0x01 0xbd 0x02 0x17 0x01 0xbd >;
				linux,phandle = < 0x1c >;
				phandle = < 0x1c >;
			};

			sdio0-cmd {
				rockchip,pins = < 0x02 0x18 0x01 0xbd >;
				linux,phandle = < 0x1d >;
				phandle = < 0x1d >;
			};

			sdio0-clk {
				rockchip,pins = < 0x02 0x19 0x01 0xbf >;
				linux,phandle = < 0x1e >;
				phandle = < 0x1e >;
			};

			sdio0-cd {
				rockchip,pins = < 0x02 0x1a 0x01 0xbd >;
			};

			sdio0-pwr {
				rockchip,pins = < 0x02 0x1b 0x01 0xbd >;
			};

			sdio0-bkpwr {
				rockchip,pins = < 0x02 0x1c 0x01 0xbd >;
			};

			sdio0-wp {
				rockchip,pins = < 0x00 0x03 0x01 0xbd >;
			};

			sdio0-int {
				rockchip,pins = < 0x00 0x04 0x01 0xbd >;
			};
		};

		sdmmc {

			sdmmc-bus1 {
				rockchip,pins = < 0x04 0x08 0x01 0xbd >;
			};

			sdmmc-bus4 {
				rockchip,pins = < 0x04 0x08 0x01 0xbd 0x04 0x09 0x01 0xbd 0x04 0x0a 0x01 0xbd 0x04 0x0b 0x01 0xbd >;
				linux,phandle = < 0x23 >;
				phandle = < 0x23 >;
			};

			sdmmc-clk {
				rockchip,pins = < 0x04 0x0c 0x01 0xbf >;
				linux,phandle = < 0x20 >;
				phandle = < 0x20 >;
			};

			sdmmc-cmd {
				rockchip,pins = < 0x04 0x0d 0x01 0xbd >;
				linux,phandle = < 0x21 >;
				phandle = < 0x21 >;
			};

			sdmcc-cd {
				rockchip,pins = < 0x00 0x07 0x01 0xbd >;
				linux,phandle = < 0x22 >;
				phandle = < 0x22 >;
			};

			sdmmc-wp {
				rockchip,pins = < 0x00 0x08 0x01 0xbd >;
			};
		};

		spdif {

			spdif-bus {
				rockchip,pins = < 0x04 0x15 0x01 0xbf >;
				linux,phandle = < 0x99 >;
				phandle = < 0x99 >;
			};

			spdif-bus-1 {
				rockchip,pins = < 0x03 0x10 0x03 0xbf >;
			};
		};

		spi0 {

			spi0-clk {
				rockchip,pins = < 0x03 0x06 0x02 0xbd >;
				linux,phandle = < 0x49 >;
				phandle = < 0x49 >;
			};

			spi0-cs0 {
				rockchip,pins = < 0x03 0x07 0x02 0xbd >;
				linux,phandle = < 0x4c >;
				phandle = < 0x4c >;
			};

			spi0-cs1 {
				rockchip,pins = < 0x03 0x08 0x02 0xbd >;
			};

			spi0-tx {
				rockchip,pins = < 0x03 0x05 0x02 0xbd >;
				linux,phandle = < 0x4a >;
				phandle = < 0x4a >;
			};

			spi0-rx {
				rockchip,pins = < 0x03 0x04 0x02 0xbd >;
				linux,phandle = < 0x4b >;
				phandle = < 0x4b >;
			};
		};

		spi1 {

			spi1-clk {
				rockchip,pins = < 0x01 0x09 0x02 0xbd >;
				linux,phandle = < 0x4d >;
				phandle = < 0x4d >;
			};

			spi1-cs0 {
				rockchip,pins = < 0x01 0x0a 0x02 0xbd >;
				linux,phandle = < 0x50 >;
				phandle = < 0x50 >;
			};

			spi1-rx {
				rockchip,pins = < 0x01 0x07 0x02 0xbd >;
				linux,phandle = < 0x4f >;
				phandle = < 0x4f >;
			};

			spi1-tx {
				rockchip,pins = < 0x01 0x08 0x02 0xbd >;
				linux,phandle = < 0x4e >;
				phandle = < 0x4e >;
			};
		};

		spi2 {

			spi2-clk {
				rockchip,pins = < 0x02 0x0b 0x01 0xbd >;
				linux,phandle = < 0x51 >;
				phandle = < 0x51 >;
			};

			spi2-cs0 {
				rockchip,pins = < 0x02 0x0c 0x01 0xbd >;
				linux,phandle = < 0x54 >;
				phandle = < 0x54 >;
			};

			spi2-rx {
				rockchip,pins = < 0x02 0x09 0x01 0xbd >;
				linux,phandle = < 0x53 >;
				phandle = < 0x53 >;
			};

			spi2-tx {
				rockchip,pins = < 0x02 0x0a 0x01 0xbd >;
				linux,phandle = < 0x52 >;
				phandle = < 0x52 >;
			};
		};

		spi3 {

			spi3-clk {
				rockchip,pins = < 0x01 0x11 0x01 0xbd >;
				linux,phandle = < 0x7c >;
				phandle = < 0x7c >;
			};

			spi3-cs0 {
				rockchip,pins = < 0x01 0x12 0x01 0xbd >;
				linux,phandle = < 0x7f >;
				phandle = < 0x7f >;
			};

			spi3-rx {
				rockchip,pins = < 0x01 0x0f 0x01 0xbd >;
				linux,phandle = < 0x7e >;
				phandle = < 0x7e >;
			};

			spi3-tx {
				rockchip,pins = < 0x01 0x10 0x01 0xbd >;
				linux,phandle = < 0x7d >;
				phandle = < 0x7d >;
			};
		};

		spi4 {

			spi4-clk {
				rockchip,pins = < 0x03 0x02 0x02 0xbd >;
				linux,phandle = < 0x55 >;
				phandle = < 0x55 >;
			};

			spi4-cs0 {
				rockchip,pins = < 0x03 0x03 0x02 0xbd >;
				linux,phandle = < 0x58 >;
				phandle = < 0x58 >;
			};

			spi4-rx {
				rockchip,pins = < 0x03 0x00 0x02 0xbd >;
				linux,phandle = < 0x57 >;
				phandle = < 0x57 >;
			};

			spi4-tx {
				rockchip,pins = < 0x03 0x01 0x02 0xbd >;
				linux,phandle = < 0x56 >;
				phandle = < 0x56 >;
			};
		};

		spi5 {

			spi5-clk {
				rockchip,pins = < 0x02 0x16 0x02 0xbd >;
				linux,phandle = < 0x59 >;
				phandle = < 0x59 >;
			};

			spi5-cs0 {
				rockchip,pins = < 0x02 0x17 0x02 0xbd >;
				linux,phandle = < 0x5c >;
				phandle = < 0x5c >;
			};

			spi5-rx {
				rockchip,pins = < 0x02 0x14 0x02 0xbd >;
				linux,phandle = < 0x5b >;
				phandle = < 0x5b >;
			};

			spi5-tx {
				rockchip,pins = < 0x02 0x15 0x02 0xbd >;
				linux,phandle = < 0x5a >;
				phandle = < 0x5a >;
			};
		};

		tsadc {

			otp-gpio {
				rockchip,pins = < 0x01 0x06 0x00 0xbf >;
				linux,phandle = < 0x60 >;
				phandle = < 0x60 >;
			};

			otp-out {
				rockchip,pins = < 0x01 0x06 0x01 0xbf >;
				linux,phandle = < 0x61 >;
				phandle = < 0x61 >;
			};
		};

		uart0 {

			uart0-xfer {
				rockchip,pins = < 0x02 0x10 0x01 0xbd 0x02 0x11 0x01 0xbf >;
				linux,phandle = < 0x42 >;
				phandle = < 0x42 >;
			};

			uart0-cts {
				rockchip,pins = < 0x02 0x12 0x01 0xbf >;
				linux,phandle = < 0x43 >;
				phandle = < 0x43 >;
			};

			uart0-rts {
				rockchip,pins = < 0x02 0x13 0x01 0xbf >;
				linux,phandle = < 0xd0 >;
				phandle = < 0xd0 >;
			};
		};

		uart1 {

			uart1-xfer {
				rockchip,pins = < 0x03 0x0c 0x02 0xbd 0x03 0x0d 0x02 0xbf >;
				linux,phandle = < 0x44 >;
				phandle = < 0x44 >;
			};
		};

		uart2a {

			uart2a-xfer {
				rockchip,pins = < 0x04 0x08 0x02 0xbd 0x04 0x09 0x02 0xbf >;
			};
		};

		uart2b {

			uart2b-xfer {
				rockchip,pins = < 0x04 0x10 0x02 0xbd 0x04 0x11 0x02 0xbf >;
			};
		};

		uart2c {

			uart2c-xfer {
				rockchip,pins = < 0x04 0x13 0x01 0xbd 0x04 0x14 0x01 0xbf >;
				linux,phandle = < 0x45 >;
				phandle = < 0x45 >;
			};
		};

		uart3 {

			uart3-xfer {
				rockchip,pins = < 0x03 0x0e 0x02 0xbd 0x03 0x0f 0x02 0xbf >;
				linux,phandle = < 0x46 >;
				phandle = < 0x46 >;
			};

			uart3-cts {
				rockchip,pins = < 0x03 0x12 0x02 0xbf >;
				linux,phandle = < 0x47 >;
				phandle = < 0x47 >;
			};

			uart3-rts {
				rockchip,pins = < 0x03 0x13 0x02 0xbf >;
				linux,phandle = < 0x48 >;
				phandle = < 0x48 >;
			};
		};

		uart4 {

			uart4-xfer {
				rockchip,pins = < 0x01 0x07 0x01 0xbd 0x01 0x08 0x01 0xbf >;
				linux,phandle = < 0x80 >;
				phandle = < 0x80 >;
			};
		};

		uarthdcp {

			uarthdcp-xfer {
				rockchip,pins = < 0x04 0x15 0x02 0xbd 0x04 0x16 0x02 0xbf >;
			};
		};

		pwm0 {

			pwm0-pin {
				rockchip,pins = < 0x04 0x12 0x01 0xbf >;
				linux,phandle = < 0x89 >;
				phandle = < 0x89 >;
			};

			vop0-pwm-pin {
				rockchip,pins = < 0x04 0x12 0x02 0xbf >;
				linux,phandle = < 0xab >;
				phandle = < 0xab >;
			};
		};

		pwm1 {

			pwm1-pin {
				rockchip,pins = < 0x04 0x16 0x01 0xbf >;
				linux,phandle = < 0x8a >;
				phandle = < 0x8a >;
			};

			vop1-pwm-pin {
				rockchip,pins = < 0x04 0x12 0x03 0xbf >;
				linux,phandle = < 0xa4 >;
				phandle = < 0xa4 >;
			};
		};

		pwm2 {

			pwm2-pin {
				rockchip,pins = < 0x01 0x13 0x01 0xbf >;
				linux,phandle = < 0x8b >;
				phandle = < 0x8b >;
			};
		};

		pwm3a {

			pwm3a-pin {
				rockchip,pins = < 0x00 0x06 0x01 0xbf >;
				linux,phandle = < 0x8c >;
				phandle = < 0x8c >;
			};
		};

		pwm3b {

			pwm3b-pin {
				rockchip,pins = < 0x01 0x0e 0x01 0xbf >;
			};
		};

		edp {

			edp-hpd {
				rockchip,pins = < 0x04 0x17 0x02 0xbf >;
				linux,phandle = < 0xb6 >;
				phandle = < 0xb6 >;
			};
		};

		hdmi {

			hdmi-i2c-xfer {
				rockchip,pins = < 0x04 0x11 0x03 0xbf 0x04 0x10 0x03 0xbf >;
				linux,phandle = < 0xac >;
				phandle = < 0xac >;
			};

			hdmi-cec {
				rockchip,pins = < 0x04 0x17 0x01 0xbf >;
			};
		};

		pcie {

			pci-clkreqn {
				rockchip,pins = < 0x02 0x1a 0x02 0xbf >;
				linux,phandle = < 0x88 >;
				phandle = < 0x88 >;
			};

			pci-clkreqnb {
				rockchip,pins = < 0x04 0x18 0x01 0xbf >;
			};

			pci-clkreqn-cpm {
				rockchip,pins = < 0x02 0x1a 0x00 0xbf >;
			};

			pci-clkreqnb-cpm {
				rockchip,pins = < 0x04 0x18 0x00 0xbf >;
			};
		};

		pmic {

			pmic-int-l {
				rockchip,pins = < 0x01 0x15 0x00 0xbd >;
				linux,phandle = < 0x35 >;
				phandle = < 0x35 >;
			};

			pmic-dvs2 {
				rockchip,pins = < 0x01 0x12 0x00 0xc1 >;
				linux,phandle = < 0x36 >;
				phandle = < 0x36 >;
			};

			vsel1-gpio {
				rockchip,pins = < 0x01 0x11 0x00 0xc1 >;
				linux,phandle = < 0x32 >;
				phandle = < 0x32 >;
			};

			vsel2-gpio {
				rockchip,pins = < 0x01 0x0e 0x00 0xc1 >;
				linux,phandle = < 0x34 >;
				phandle = < 0x34 >;
			};
		};

		usb2 {

			host-vbus-drv {
				rockchip,pins = < 0x04 0x19 0x00 0xbf >;
				linux,phandle = < 0xca >;
				phandle = < 0xca >;
			};
		};

		fusb30x {

			fusb0-int {
				rockchip,pins = < 0x01 0x02 0x00 0xbd >;
				linux,phandle = < 0x82 >;
				phandle = < 0x82 >;
			};
		};

		sdio-pwrseq {

			wifi-enable-h {
				rockchip,pins = < 0x00 0x0a 0x00 0xbf >;
				linux,phandle = < 0xc9 >;
				phandle = < 0xc9 >;
			};
		};

		wireless-bluetooth {

			uart0-gpios {
				rockchip,pins = < 0x02 0x13 0x00 0xbf >;
				linux,phandle = < 0xd1 >;
				phandle = < 0xd1 >;
			};
		};

		mpu6500 {

			mpu6500-irq-gpio {
				rockchip,pins = < 0x01 0x00 0x00 0xbf >;
			};
		};

		charger {

			charge-ok {
				rockchip,pins = < 0x01 0x17 0x00 0xbd >;
			};
		};

		isp {

			cif-clkout {
				rockchip,pins = < 0x02 0x0b 0x03 0xbf >;
				linux,phandle = < 0xd5 >;
				phandle = < 0xd5 >;
			};

			isp-dvp-d0d7 {
				rockchip,pins = < 0x02 0x00 0x03 0xbf 0x02 0x01 0x03 0xbf 0x02 0x02 0x03 0xbf 0x02 0x03 0x03 0xbf 0x02 0x04 0x03 0xbf 0x02 0x05 0x03 0xbf 0x02 0x06 0x03 0xbf 0x02 0x07 0x03 0xbf 0x02 0x08 0x03 0xbf 0x02 0x09 0x03 0xbf 0x02 0x0a 0x03 0xbf >;
				linux,phandle = < 0xd6 >;
				phandle = < 0xd6 >;
			};

			isp-shutter {
				rockchip,pins = < 0x01 0x01 0x01 0xbf 0x01 0x00 0x01 0xbf >;
			};

			isp-flash-trigger {
				rockchip,pins = < 0x01 0x03 0x01 0xbf >;
				linux,phandle = < 0xd9 >;
				phandle = < 0xd9 >;
			};

			isp-prelight {
				rockchip,pins = < 0x01 0x04 0x01 0xbf >;
				linux,phandle = < 0xd7 >;
				phandle = < 0xd7 >;
			};

			isp_flash_trigger_as_gpio {
				rockchip,pins = < 0x01 0x03 0x00 0xbf >;
				linux,phandle = < 0xd8 >;
				phandle = < 0xd8 >;
			};
		};

		lcd-panel {

			lcd-panel-reset {
				rockchip,pins = < 0x04 0x1e 0x00 0xbd >;
			};
		};

		hdmiin {

			hdmiin_gpios {
				rockchip,pins = < 0x02 0x05 0x00 0xbf 0x02 0x06 0x00 0xbf 0x02 0x07 0x00 0xbf 0x02 0x08 0x00 0xbf 0x02 0x09 0x00 0xbf 0x02 0x0c 0x00 0xbf >;
			};
		};

		headphone {

			hp-det {
				rockchip,pins = < 0x04 0x1c 0x00 0xbd >;
				linux,phandle = < 0xdd >;
				phandle = < 0xdd >;
			};
		};
	};

	rockchip-suspend {
		compatible = "rockchip,pm-rk3399";
		status = "okay";
		rockchip,sleep-debug-en = < 0x01 >;
		rockchip,virtual-poweroff = < 0x00 >;
		rockchip,sleep-mode-config = < 0xde >;
		rockchip,wakeup-config = < 0x804 >;
		rockchip,pwm-regulator-config = < 0x04 >;
		rockchip,power-ctrl = < 0x33 0x11 0x00 0x33 0x0e 0x00 >;
	};

	energy-costs {

		rk3399-core-cost0 {
			busy-cost-data = < 0x6c 0x2e 0x9f 0x43 0xd8 0x5a 0x10b 0x78 0x13e 0x99 0x177 0xc6 0x191 0xde >;
			idle-cost-data = < 0x06 0x06 0x00 0x00 >;
			linux,phandle = < 0x0c >;
			phandle = < 0x0c >;
		};

		rk3399-core-cost1 {
			busy-cost-data = < 0xd2 0x81 0x134 0xb8 0x1a3 0xf6 0x206 0x14f 0x269 0x1ac 0x2d8 0x23d 0x33b 0x2d4 0x39d 0x384 0x400 0x454 >;
			idle-cost-data = < 0x0f 0x0f 0x00 0x00 >;
			linux,phandle = < 0x10 >;
			phandle = < 0x10 >;
		};

		rk3399-cluster-cost0 {
			busy-cost-data = < 0x6c 0x2e 0x9f 0x43 0xd8 0x5a 0x10b 0x78 0x13e 0x99 0x177 0xc6 0x191 0xde >;
			idle-cost-data = < 0x38 0x38 0x38 0x38 >;
			linux,phandle = < 0x0d >;
			phandle = < 0x0d >;
		};

		rk3399-cluster-cost1 {
			busy-cost-data = < 0xd2 0x81 0x134 0xb8 0x1a3 0xf6 0x206 0x14f 0x269 0x1ac 0x2d8 0x23d 0x33b 0x2d4 0x39d 0x384 0x400 0x454 >;
			idle-cost-data = < 0x41 0x41 0x41 0x41 >;
			linux,phandle = < 0x11 >;
			phandle = < 0x11 >;
		};
	};

	opp-table0 {
		compatible = "operating-points-v2";
		opp-shared;
		nvmem-cells = < 0xc2 >;
		nvmem-cell-names = "cpu_leakage";
		rockchip,pvtm-voltage-sel = < 0x00 0x2308c 0x00 0x2308d 0x24414 0x01 0x24415 0x251c0 0x02 0x251c1 0xf423f 0x03 >;
		rockchip,pvtm-freq = < 0x639c0 >;
		rockchip,pvtm-volt = < 0xf4240 >;
		rockchip,pvtm-ch = < 0x00 0x00 >;
		rockchip,pvtm-sample-time = < 0x3e8 >;
		rockchip,pvtm-number = < 0x0a >;
		rockchip,pvtm-error = < 0x3e8 >;
		rockchip,pvtm-ref-temp = < 0x29 >;
		rockchip,pvtm-temp-prop = < 0x73 0x42 >;
		rockchip,pvtm-thermal-zone = "soc-thermal";
		linux,phandle = < 0x0b >;
		phandle = < 0x0b >;

		opp-408000000 {
			opp-hz = < 0x00 0x18519600 >;
			opp-microvolt = < 0xc3500 >;
			opp-microvolt-L0 = < 0xc3500 >;
			opp-microvolt-L1 = < 0xc3500 >;
			opp-microvolt-L2 = < 0xc3500 >;
			opp-microvolt-L3 = < 0xc3500 >;
			clock-latency-ns = < 0x9c40 >;
		};

		opp-600000000 {
			opp-hz = < 0x00 0x23c34600 >;
			opp-microvolt = < 0xc3500 >;
			opp-microvolt-L0 = < 0xc3500 >;
			opp-microvolt-L1 = < 0xc3500 >;
			opp-microvolt-L2 = < 0xc3500 >;
			opp-microvolt-L3 = < 0xc3500 >;
			clock-latency-ns = < 0x9c40 >;
		};

		opp-816000000 {
			opp-hz = < 0x00 0x30a32c00 >;
			opp-microvolt = < 0xcf850 >;
			opp-microvolt-L0 = < 0xcf850 >;
			opp-microvolt-L1 = < 0xc96a8 >;
			opp-microvolt-L2 = < 0xc3500 >;
			opp-microvolt-L3 = < 0xc3500 >;
			clock-latency-ns = < 0x9c40 >;
			opp-suspend;
		};

		opp-1008000000 {
			opp-hz = < 0x00 0x3c14dc00 >;
			opp-microvolt = < 0xe1d48 >;
			opp-microvolt-L0 = < 0xe1d48 >;
			opp-microvolt-L1 = < 0xdbba0 >;
			opp-microvolt-L2 = < 0xd59f8 >;
			opp-microvolt-L3 = < 0xcf850 >;
			clock-latency-ns = < 0x9c40 >;
		};

		opp-1200000000 {
			opp-hz = < 0x00 0x47868c00 >;
			opp-microvolt = < 0xf4240 >;
			opp-microvolt-L0 = < 0xf4240 >;
			opp-microvolt-L1 = < 0xee098 >;
			opp-microvolt-L2 = < 0xe7ef0 >;
			opp-microvolt-L3 = < 0xe1d48 >;
			clock-latency-ns = < 0x9c40 >;
		};

		opp-1416000000 {
			opp-hz = < 0x00 0x54667200 >;
			opp-microvolt = < 0x112a88 >;
			opp-microvolt-L0 = < 0x112a88 >;
			opp-microvolt-L1 = < 0x10c8e0 >;
			opp-microvolt-L2 = < 0x106738 >;
			opp-microvolt-L3 = < 0x100590 >;
			clock-latency-ns = < 0x9c40 >;
		};
	};

	opp-table1 {
		compatible = "operating-points-v2";
		opp-shared;
		nvmem-cells = < 0xc3 >;
		nvmem-cell-names = "cpu_leakage";
		rockchip,pvtm-voltage-sel = < 0x00 0x24608 0x00 0x24609 0x25d78 0x01 0x25d79 0x27100 0x02 0x27101 0xf423f 0x03 >;
		rockchip,pvtm-freq = < 0x639c0 >;
		rockchip,pvtm-volt = < 0xf4240 >;
		rockchip,pvtm-ch = < 0x01 0x00 >;
		rockchip,pvtm-sample-time = < 0x3e8 >;
		rockchip,pvtm-number = < 0x0a >;
		rockchip,pvtm-error = < 0x3e8 >;
		rockchip,pvtm-ref-temp = < 0x29 >;
		rockchip,pvtm-temp-prop = < 0x47 0x23 >;
		rockchip,pvtm-thermal-zone = "soc-thermal";
		linux,phandle = < 0x0f >;
		phandle = < 0x0f >;

		opp-408000000 {
			opp-hz = < 0x00 0x18519600 >;
			opp-microvolt = < 0xc3500 >;
			opp-microvolt-L0 = < 0xc3500 >;
			opp-microvolt-L1 = < 0xc3500 >;
			opp-microvolt-L2 = < 0xc3500 >;
			opp-microvolt-L3 = < 0xc3500 >;
			clock-latency-ns = < 0x9c40 >;
		};

		opp-600000000 {
			opp-hz = < 0x00 0x23c34600 >;
			opp-microvolt = < 0xc3500 >;
			opp-microvolt-L0 = < 0xc3500 >;
			opp-microvolt-L1 = < 0xc3500 >;
			opp-microvolt-L2 = < 0xc3500 >;
			opp-microvolt-L3 = < 0xc3500 >;
			clock-latency-ns = < 0x9c40 >;
		};

		opp-816000000 {
			opp-hz = < 0x00 0x30a32c00 >;
			opp-microvolt = < 0xc96a8 >;
			opp-microvolt-L0 = < 0xc96a8 >;
			opp-microvolt-L1 = < 0xc96a8 >;
			opp-microvolt-L2 = < 0xc3500 >;
			opp-microvolt-L3 = < 0xc3500 >;
			clock-latency-ns = < 0x9c40 >;
			opp-suspend;
		};

		opp-1008000000 {
			opp-hz = < 0x00 0x3c14dc00 >;
			opp-microvolt = < 0xd59f8 >;
			opp-microvolt-L0 = < 0xd59f8 >;
			opp-microvolt-L1 = < 0xcf850 >;
			opp-microvolt-L2 = < 0xcf850 >;
			opp-microvolt-L3 = < 0xcf850 >;
			clock-latency-ns = < 0x9c40 >;
		};

		opp-1200000000 {
			opp-hz = < 0x00 0x47868c00 >;
			opp-microvolt = < 0xe7ef0 >;
			opp-microvolt-L0 = < 0xe7ef0 >;
			opp-microvolt-L1 = < 0xe1d48 >;
			opp-microvolt-L2 = < 0xdbba0 >;
			opp-microvolt-L3 = < 0xd59f8 >;
			clock-latency-ns = < 0x9c40 >;
		};

		opp-1416000000 {
			opp-hz = < 0x00 0x54667200 >;
			opp-microvolt = < 0xfa3e8 >;
			opp-microvolt-L0 = < 0xfa3e8 >;
			opp-microvolt-L1 = < 0xf4240 >;
			opp-microvolt-L2 = < 0xf4240 >;
			opp-microvolt-L3 = < 0xee098 >;
			clock-latency-ns = < 0x9c40 >;
		};

		opp-1608000000 {
			opp-hz = < 0x00 0x5fd82200 >;
			opp-microvolt = < 0x10c8e0 >;
			opp-microvolt-L0 = < 0x10c8e0 >;
			opp-microvolt-L1 = < 0x106738 >;
			opp-microvolt-L2 = < 0x100590 >;
			opp-microvolt-L3 = < 0xfa3e8 >;
			clock-latency-ns = < 0x9c40 >;
		};

		opp-1800000000 {
			opp-hz = < 0x00 0x6b49d200 >;
			opp-microvolt = < 0x124f80 >;
			opp-microvolt-L0 = < 0x124f80 >;
			opp-microvolt-L1 = < 0x11edd8 >;
			opp-microvolt-L2 = < 0x118c30 >;
			opp-microvolt-L3 = < 0x112a88 >;
			clock-latency-ns = < 0x9c40 >;
		};
	};

	opp-table2 {
		compatible = "operating-points-v2";
		nvmem-cells = < 0xc4 >;
		nvmem-cell-names = "gpu_leakage";
		rockchip,pvtm-voltage-sel = < 0x00 0x1d8a8 0x00 0x1d8a9 0x1ea3c 0x01 0x1ea3d 0x1f5f4 0x02 0x1f5f5 0xf423f 0x03 >;
		rockchip,pvtm-freq = < 0x30d40 >;
		rockchip,pvtm-volt = < 0xdbba0 >;
		rockchip,pvtm-ch = < 0x03 0x00 >;
		rockchip,pvtm-sample-time = < 0x3e8 >;
		rockchip,pvtm-number = < 0x0a >;
		rockchip,pvtm-error = < 0x3e8 >;
		rockchip,pvtm-ref-temp = < 0x29 >;
		rockchip,pvtm-temp-prop = < 0x2e 0x0c >;
		rockchip,pvtm-thermal-zone = "gpu-thermal";
		linux,phandle = < 0x9c >;
		phandle = < 0x9c >;

		opp-200000000 {
			opp-hz = < 0x00 0xbebc200 >;
			opp-microvolt = < 0xc3500 >;
			opp-microvolt-L0 = < 0xc3500 >;
			opp-microvolt-L1 = < 0xc3500 >;
			opp-microvolt-L2 = < 0xc3500 >;
			opp-microvolt-L3 = < 0xc3500 >;
		};

		opp-300000000 {
			opp-hz = < 0x00 0x11e1a300 >;
			opp-microvolt = < 0xc3500 >;
			opp-microvolt-L0 = < 0xc3500 >;
			opp-microvolt-L1 = < 0xc3500 >;
			opp-microvolt-L2 = < 0xc3500 >;
			opp-microvolt-L3 = < 0xc3500 >;
		};

		opp-400000000 {
			opp-hz = < 0x00 0x17d78400 >;
			opp-microvolt = < 0xc96a8 >;
			opp-microvolt-L0 = < 0xc96a8 >;
			opp-microvolt-L1 = < 0xc96a8 >;
			opp-microvolt-L2 = < 0xc3500 >;
			opp-microvolt-L3 = < 0xc3500 >;
		};

		opp-600000000 {
			opp-hz = < 0x00 0x23c34600 >;
			opp-microvolt = < 0xe1d48 >;
			opp-microvolt-L0 = < 0xe1d48 >;
			opp-microvolt-L1 = < 0xe1d48 >;
			opp-microvolt-L2 = < 0xdbba0 >;
			opp-microvolt-L3 = < 0xdbba0 >;
		};

		opp-800000000 {
			opp-hz = < 0x00 0x2faf0800 >;
			opp-microvolt = < 0x10c8e0 >;
			opp-microvolt-L0 = < 0x10c8e0 >;
			opp-microvolt-L1 = < 0x106738 >;
			opp-microvolt-L2 = < 0x100590 >;
			opp-microvolt-L3 = < 0xfa3e8 >;
		};
	};

	opp-table3 {
		compatible = "operating-points-v2";
		linux,phandle = < 0x90 >;
		phandle = < 0x90 >;

		opp-200000000 {
			opp-hz = < 0x00 0xbebc200 >;
			opp-microvolt = < 0xc96a8 >;
		};

		opp-300000000 {
			opp-hz = < 0x00 0x11e1a300 >;
			opp-microvolt = < 0xcf850 >;
		};

		opp-400000000 {
			opp-hz = < 0x00 0x17d78400 >;
			opp-microvolt = < 0xcf850 >;
		};

		opp-528000000 {
			opp-hz = < 0x00 0x1f78a400 >;
			opp-microvolt = < 0xdbba0 >;
		};

		opp-600000000 {
			opp-hz = < 0x00 0x23c34600 >;
			opp-microvolt = < 0xdbba0 >;
		};

		opp-800000000 {
			opp-hz = < 0x00 0x2faf0800 >;
			opp-microvolt = < 0xdbba0 >;
		};
	};

	backlight {
		status = "okay";
		compatible = "pwm-backlight";
		pwms = < 0xc5 0x00 0x61a8 0x00 >;
		brightness-levels = < 0x00 0x01 0x02 0x03 0x04 0x05 0x06 0x07 0x08 0x09 0x0a 0x0b 0x0c 0x0d 0x0e 0x0f 0x10 0x11 0x12 0x13 0x14 0x15 0x16 0x17 0x18 0x19 0x1a 0x1b 0x1c 0x1d 0x1e 0x1f 0x20 0x21 0x22 0x23 0x24 0x25 0x26 0x27 0x28 0x29 0x2a 0x2b 0x2c 0x2d 0x2e 0x2f 0x30 0x31 0x32 0x33 0x34 0x35 0x36 0x37 0x38 0x39 0x3a 0x3b 0x3c 0x3d 0x3e 0x3f 0x40 0x41 0x42 0x43 0x44 0x45 0x46 0x47 0x48 0x49 0x4a 0x4b 0x4c 0x4d 0x4e 0x4f 0x50 0x51 0x52 0x53 0x54 0x55 0x56 0x57 0x58 0x59 0x5a 0x5b 0x5c 0x5d 0x5e 0x5f 0x60 0x61 0x62 0x63 0x64 0x65 0x66 0x67 0x68 0x69 0x6a 0x6b 0x6c 0x6d 0x6e 0x6f 0x70 0x71 0x72 0x73 0x74 0x75 0x76 0x77 0x78 0x79 0x7a 0x7b 0x7c 0x7d 0x7e 0x7f 0x80 0x81 0x82 0x83 0x84 0x85 0x86 0x87 0x88 0x89 0x8a 0x8b 0x8c 0x8d 0x8e 0x8f 0x90 0x91 0x92 0x93 0x94 0x95 0x96 0x97 0x98 0x99 0x9a 0x9b 0x9c 0x9d 0x9e 0x9f 0xa0 0xa1 0xa2 0xa3 0xa4 0xa5 0xa6 0xa7 0xa8 0xa9 0xaa 0xab 0xac 0xad 0xae 0xaf 0xb0 0xb1 0xb2 0xb3 0xb4 0xb5 0xb6 0xb7 0xb8 0xb9 0xba 0xbb 0xbc 0xbd 0xbe 0xbf 0xc0 0xc1 0xc2 0xc3 0xc4 0xc5 0xc6 0xc7 0xc8 0xc9 0xca 0xcb 0xcc 0xcd 0xce 0xcf 0xd0 0xd1 0xd2 0xd3 0xd4 0xd5 0xd6 0xd7 0xd8 0xd9 0xda 0xdb 0xdc 0xdd 0xde 0xdf 0xe0 0xe1 0xe2 0xe3 0xe4 0xe5 0xe6 0xe7 0xe8 0xe9 0xea 0xeb 0xec 0xed 0xee 0xef 0xf0 0xf1 0xf2 0xf3 0xf4 0xf5 0xf6 0xf7 0xf8 0xf9 0xfa 0xfb 0xfc 0xfd 0xfe 0xff >;
		default-brightness-level = < 0xc8 >;
		enable-gpios = < 0x3c 0x1d 0x00 >;
		linux,phandle = < 0xb1 >;
		phandle = < 0xb1 >;
	};

	external-gmac-clock {
		compatible = "fixed-clock";
		clock-frequency = < 0x7735940 >;
		clock-output-names = "clkin_gmac";
		#clock-cells = < 0x00 >;
		linux,phandle = < 0x19 >;
		phandle = < 0x19 >;
	};

	dw-hdmi-audio {
		status = "disabled";
		compatible = "rockchip,dw-hdmi-audio";
		#sound-dai-cells = < 0x00 >;
	};

	hdmi-sound {
		status = "disabled";
		compatible = "simple-audio-card";
		simple-audio-card,format = "i2s";
		simple-audio-card,mclk-fs = < 0x100 >;
		simple-audio-card,name = "rockchip,hdmi";

		simple-audio-card,cpu {
			sound-dai = < 0xc6 >;
		};

		simple-audio-card,codec {
			sound-dai = < 0xc7 >;
		};
	};

	sdio-pwrseq {
		compatible = "mmc-pwrseq-simple";
		clocks = < 0xc8 0x01 >;
		clock-names = "ext_clock";
		pinctrl-names = "default";
		pinctrl-0 = < 0xc9 >;
		reset-gpios = < 0x3b 0x0a 0x01 >;
		linux,phandle = < 0x1b >;
		phandle = < 0x1b >;
	};

	vcc3v3-sys {
		compatible = "regulator-fixed";
		regulator-name = "vcc3v3_sys";
		regulator-always-on;
		regulator-boot-on;
		regulator-min-microvolt = < 0x325aa0 >;
		regulator-max-microvolt = < 0x325aa0 >;
		linux,phandle = < 0x37 >;
		phandle = < 0x37 >;
	};

	vcc5v0-host-regulator {
		compatible = "regulator-fixed";
		enable-active-high;
		gpio = < 0x3c 0x19 0x00 >;
		pinctrl-names = "default";
		pinctrl-0 = < 0xca >;
		regulator-name = "vcc5v0_host";
		regulator-always-on;
		linux,phandle = < 0x97 >;
		phandle = < 0x97 >;
	};

	vcc5v0-sys {
		compatible = "regulator-fixed";
		regulator-name = "vcc5v0_sys";
		regulator-always-on;
		regulator-boot-on;
		regulator-min-microvolt = < 0x4c4b40 >;
		regulator-max-microvolt = < 0x4c4b40 >;
		linux,phandle = < 0x31 >;
		phandle = < 0x31 >;
	};

	vcc-phy-regulator {
		compatible = "regulator-fixed";
		regulator-name = "vcc_phy";
		regulator-always-on;
		regulator-boot-on;
		linux,phandle = < 0x17 >;
		phandle = < 0x17 >;
	};

	vdd-log {
		compatible = "pwm-regulator";
		pwms = < 0xcb 0x00 0x61a8 0x01 >;
		regulator-name = "vdd_log";
		regulator-min-microvolt = < 0xc3500 >;
		regulator-max-microvolt = < 0x155cc0 >;
		regulator-always-on;
		regulator-boot-on;
		rockchip,pwm_id = < 0x02 >;
		rockchip,pwm_voltage = < 0xf4240 >;
	};

	rt5651-sound {
		compatible = "simple-audio-card";
		simple-audio-card,format = "i2s";
		simple-audio-card,name = "realtek,rt5651-codec";
		simple-audio-card,mclk-fs = < 0x100 >;
		simple-audio-card,widgets = "Microphone\0Mic Jack\0Headphone\0Headphone Jack";
		simple-audio-card,routing = "Mic Jack\0MICBIAS1\0IN1P\0Mic Jack\0Headphone Jack\0HPOL\0Headphone Jack\0HPOR";
		status = "okay";

		simple-audio-card,cpu {
			sound-dai = < 0xcc >;
		};

		simple-audio-card,codec {
			sound-dai = < 0xcd >;
		};
	};

	spdif-sound {
		status = "okay";
		compatible = "simple-audio-card";
		simple-audio-card,name = "ROCKCHIP,SPDIF";

		simple-audio-card,cpu {
			sound-dai = < 0xce >;
		};

		simple-audio-card,codec {
			sound-dai = < 0xcf >;
		};
	};

	spdif-out {
		status = "okay";
		compatible = "linux,spdif-dit";
		#sound-dai-cells = < 0x00 >;
		linux,phandle = < 0xcf >;
		phandle = < 0xcf >;
	};

	wireless-wlan {
		compatible = "wlan-platdata";
		rockchip,grf = < 0x15 >;
		wifi_chip_type = "ap6354";
		sdio_vref = < 0x708 >;
		WIFI,host_wake_irq = < 0x3b 0x03 0x00 >;
		status = "okay";
	};

	wireless-bluetooth {
		compatible = "bluetooth-platdata";
		clocks = < 0xc8 0x01 >;
		clock-names = "ext_clock";
		uart_rts_gpios = < 0x87 0x13 0x01 >;
		pinctrl-names = "default\0rts_gpio";
		pinctrl-0 = < 0xd0 >;
		pinctrl-1 = < 0xd1 >;
		BT,reset_gpio = < 0x3b 0x09 0x00 >;
		BT,wake_gpio = < 0x87 0x1a 0x00 >;
		BT,wake_host_irq = < 0x3b 0x04 0x00 >;
		status = "okay";
	};

	chosen {
		bootargs = "earlycon=uart8250,mmio32,0xff1a0000 swiotlb=1";
	};

	cpuinfo {
		compatible = "rockchip,cpuinfo";
		nvmem-cells = < 0xd2 >;
		nvmem-cell-names = "id";
	};

	ramoops_mem {
		reg = < 0x00 0x110000 0x00 0xf0000 >;
		reg-names = "ramoops_mem";
		linux,phandle = < 0xd3 >;
		phandle = < 0xd3 >;
	};

	ramoops {
		compatible = "ramoops";
		record-size = < 0x00 0x20000 >;
		console-size = < 0x00 0x80000 >;
		ftrace-size = < 0x00 0x00 >;
		pmsg-size = < 0x00 0x50000 >;
		memory-region = < 0xd3 >;
	};

	fiq-debugger {
		compatible = "rockchip,fiq-debugger";
		rockchip,serial-id = < 0x02 >;
		rockchip,wake-irq = < 0x00 >;
		rockchip,irq-mode-enable = < 0x00 >;
		rockchip,baudrate = < 0x16e360 >;
		pinctrl-names = "default";
		pinctrl-0 = < 0x45 >;
		interrupts = < 0x00 0x96 0x04 0x00 >;
	};

	reserved-memory {
		#address-cells = < 0x02 >;
		#size-cells = < 0x02 >;
		ranges;

		drm-logo@00000000 {
			compatible = "rockchip,drm-logo";
			reg = < 0x00 0x00 0x00 0x00 >;
			linux,phandle = < 0xbb >;
			phandle = < 0xbb >;
		};

		secure-memory@e7000000 {
			compatible = "rockchip,secure-memory";
			reg = < 0x00 0xe7000000 0x00 0x10000000 >;
			status = "disabled";
			linux,phandle = < 0xbc >;
			phandle = < 0xbc >;
		};

		stb-devinfo@00000000 {
			compatible = "rockchip,stb-devinfo";
			reg = < 0x00 0x00 0x00 0x00 >;
		};
	};

	rockchip-key {
		compatible = "rockchip,key";
		status = "okay";
		io-channels = < 0xd4 0x01 >;

		vol-up-key {
			linux,code = < 0x73 >;
			label = "volume up";
			rockchip,adc_value = < 0x01 >;
		};

		vol-down-key {
			linux,code = < 0x72 >;
			label = "volume down";
			rockchip,adc_value = < 0xaa >;
		};

		power-key {
			gpios = < 0x3b 0x05 0x01 >;
			linux,code = < 0x74 >;
			label = "power";
			gpio-key,wakeup;
		};

		menu-key {
			linux,code = < 0x3b >;
			label = "menu";
			rockchip,adc_value = < 0x2ea >;
		};

		home-key {
			linux,code = < 0x66 >;
			label = "home";
			rockchip,adc_value = < 0x163 >;
		};

		back-key {
			linux,code = < 0x9e >;
			label = "back";
			rockchip,adc_value = < 0x230 >;
		};

		camera-key {
			linux,code = < 0xd4 >;
			label = "camera";
			rockchip,adc_value = < 0x1c2 >;
		};
	};

	isp@ff910000 {
		compatible = "rockchip,rk3399-isp\0rockchip,isp";
		reg = < 0x00 0xff910000 0x00 0x4000 >;
		interrupts = < 0x00 0x2b 0x04 0x00 >;
		clocks = < 0x08 0x89 0x08 0x89 0x08 0xa4 0x08 0x77 0x08 0xe7 0x08 0xe9 0x08 0x1e1 0x08 0x1e3 0x08 0x6e 0x08 0xa5 >;
		clock-names = "clk_cif_out\0clk_cif_pll\0pclk_dphytxrx\0pclk_dphy_ref\0aclk_isp0_noc\0aclk_isp0_wrapper\0hclk_isp0_noc\0hclk_isp0_wrapper\0clk_isp0\0pclk_dphyrx";
		pinctrl-names = "cif_clkout\0isp_dvp8bit0\0isp_mipi_fl\0isp_mipi_fl_prefl\0isp_flash_as_gpio\0isp_flash_as_trigger_out";
		pinctrl-0 = < 0xd5 >;
		pinctrl-1 = < 0xd6 >;
		pinctrl-2 = < 0xd5 >;
		pinctrl-3 = < 0xd7 >;
		pinctrl-4 = < 0xd8 >;
		pinctrl-5 = < 0xd9 >;
		rockchip,isp,mipiphy = < 0x02 >;
		rockchip,isp,cifphy = < 0x01 >;
		rockchip,isp,dsiphy,reg = < 0xff968000 0x8000 >;
		rockchip,grf = < 0x15 >;
		rockchip,cru = < 0x08 >;
		rockchip,gpios = < 0x33 0x03 0x00 >;
		rockchip,isp,iommu-enable = < 0x01 >;
		power-domains = < 0x16 0x13 >;
		iommus = < 0xda >;
		status = "okay";
	};

	isp@ff920000 {
		compatible = "rockchip,rk3399-isp\0rockchip,isp";
		reg = < 0x00 0xff920000 0x00 0x4000 >;
		interrupts = < 0x00 0x2c 0x04 0x00 >;
		clocks = < 0x08 0xe8 0x08 0xea 0x08 0x1e2 0x08 0x1e4 0x08 0x6f 0x08 0x89 0x08 0x89 0x08 0xa4 0x08 0x77 0x08 0x17b 0x08 0xa5 0x08 0x171 0x08 0x78 >;
		clock-names = "aclk_isp1_noc\0aclk_isp1_wrapper\0hclk_isp1_noc\0hclk_isp1_wrapper\0clk_isp1\0clk_cif_out\0clk_cif_pll\0pclk_dphytxrx\0pclk_dphy_ref\0pclk_isp1\0pclk_dphyrx\0pclk_mipi_dsi\0mipi_dphy_cfg";
		pinctrl-names = "cif_clkout\0isp_dvp8bit0\0isp_mipi_fl\0isp_mipi_fl_prefl\0isp_flash_as_gpio\0isp_flash_as_trigger_out";
		pinctrl-0 = < 0xd5 >;
		pinctrl-1 = < 0xd6 >;
		pinctrl-2 = < 0xd5 >;
		pinctrl-3 = < 0xd7 >;
		pinctrl-4 = < 0xd8 >;
		pinctrl-5 = < 0xd9 >;
		rockchip,isp,mipiphy = < 0x02 >;
		rockchip,isp,cifphy = < 0x01 >;
		rockchip,isp,dsiphy,reg = < 0xff968000 0x8000 >;
		rockchip,grf = < 0x15 >;
		rockchip,cru = < 0x08 >;
		rockchip,gpios = < 0x33 0x03 0x00 >;
		rockchip,isp,iommu-enable = < 0x01 >;
		power-domains = < 0x16 0x14 >;
		iommus = < 0xdb >;
		status = "okay";
	};

	uboot-charge {
		compatible = "rockchip,uboot-charge";
		rockchip,uboot-charge-on = < 0x01 >;
		rockchip,android-charge-on = < 0x00 >;
	};

	hdmi-dp-sound {
		status = "okay";
		compatible = "rockchip,rk3399-hdmi-dp";
		rockchip,cpu = < 0xc6 >;
		rockchip,codec = < 0xc7 0xdc >;
	};

	test-power {
		status = "okay";
	};

	rk_headset {
		compatible = "rockchip_headset";
		headset_gpio = < 0x3c 0x1c 0x01 >;
		pinctrl-names = "default";
		pinctrl-0 = < 0xdd >;
		io-channels = < 0xd4 0x02 >;
	};
};
